[part 1 of 2: package /Vehicle_CAN_Bus_J1939/Clusters]
AUTOSAR XML (schema 4-1-3)
package /Vehicle_CAN_Bus_J1939/Clusters
  can cluster Vehicle_CAN_Bus_J1939
    can physical channel CANChannel
      comm-connectors:
        Thermal_Management_System_ECU_CANConnector
        DMU_VEDS_CANConnector
        VIC_CANConnector
        Vehicle_Control_Unit_CANConnector
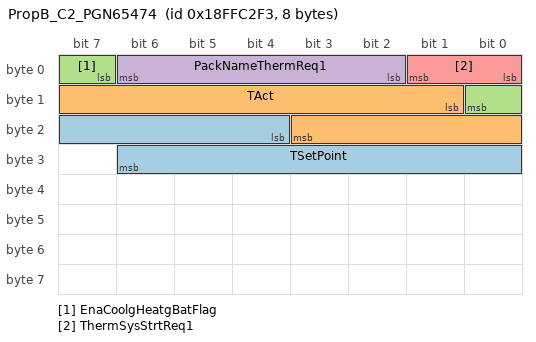
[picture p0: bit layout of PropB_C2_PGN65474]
      frame PropB_C2_PGN65474: id 0x18FFC2F3, from VIC, to Thermal_Management_System_ECU, frame-length=8, can-addressing-mode=EXTENDED  # Coolant/heating request for an external thermal management system with setpoint control
        pdu PropB_C2_PGN65474: length=8, transmission-mode-condition{data-filter=data-filter-type=ALWAYS, i-signal-in-i-pdu=PropB_C2_PGN65474_TSetPoint}, transmission-mode-true-timing=cyclic-timing=time-period=0.1
          signal TSetPoint: start 20, 11 bit, little-endian, data-type-policy=OVERRIDE, init-value=1024, base-type=TSetPoint_Coding, compu {phys=raw*0.25-256; unit °C}, range phys -256..255.75, unit=°C, to Thermal_Management_System_ECU  # Setpoint temperature for an external thermal management system for pack mentioned in PackNameThermReq1 (multiplexed signal)
          signal TAct: start 9, 11 bit, little-endian, data-type-policy=OVERRIDE, init-value=1024, base-type=TAct_Coding, compu {phys=raw*0.25-256; unit °C}, range phys -256..255.75, unit=°C, to Thermal_Management_System_ECU  # Cell temperature of pack mentioned in PackNameThermReq1 with the highest absolute deviation from the setpoint temperature (multiplexed signal)
          signal EnaCoolgHeatgBatFlag: start 7, 2 bit, little-endian, data-type-policy=OVERRIDE, init-value=0, base-type=EnaCoolgHeatgBatFlag_Coding, compu {3=Info not available (default), 2=Reserved, 1=Activate, 0=Deactivate}, range phys 0..3, to Thermal_Management_System_ECU  # Request for coolant/heating flow for an external thermal management system with setpoint control from pack mentioned in PackNameThermReq1 (multiplexed signal)
          signal PackNameThermReq1: start 2, 5 bit, little-endian, data-type-policy=OVERRIDE, init-value=0, base-type=PackNameThermReq1_Coding, compu {31=Info not available, 30=VIC, 12=Pack2_6, 11=Pack2_5, 10=Pack2_4, 9=Pack2_3, 8=Pack2_2, 7=Pack2_1, 6=Pack1_7, 5=Pack1_6, 4=Pack1_5, 3=Pack1_4, 2=Pack1_3, 1=Pack1_2, 0=Pack1_1 or Standalone}, range phys 0..31, to Thermal_Management_System_ECU  # Battery pack the multiplexed signals in this message refer to (multiplexor signal)
          signal ThermSysStrtReq1: start 0, 2 bit, little-endian, data-type-policy=OVERRIDE, init-value=0, base-type=ThermSysStrtReq1_Coding, compu {3=Info not available (default), 2=Reserved, 1=Active, 0=Not active}, range phys 0..3, to Thermal_Management_System_ECU  # Wakeup request for an external thermal management system with setpoint control
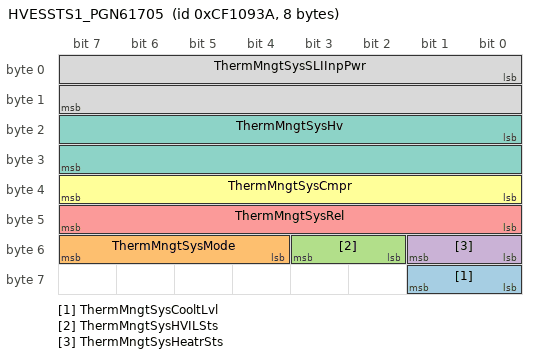
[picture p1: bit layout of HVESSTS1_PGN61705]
      frame HVESSTS1_PGN61705: id 0xCF1093A, from Thermal_Management_System_ECU, to VIC, frame-length=8, can-addressing-mode=EXTENDED  # Collection of data the High Voltage Energy Storage System Thermal Management System sends to the Hybrid Controller.
        pdu HVESSTS1_PGN61705: length=8, transmission-mode-condition{data-filter=data-filter-type=ALWAYS, i-signal-in-i-pdu=HVESSTS1_PGN61705_ThermMngtSysCooltLvl}, transmission-mode-true-timing=cyclic-timing=time-period=0.1
          signal ThermMngtSysCooltLvl: start 56, 2 bit, little-endian, data-type-policy=OVERRIDE, init-value=0, base-type=ThermMngtSysCooltLvl_Coding, compu {3=Not Available, 2=Error, 1=Coolant Level is sufficient, 0=Coolant Level is not sufficient}, range phys 0..3, to VIC  # Indicates the coolant level in the High Voltage Energy Storage System (or Pack 1 in systems with only one pack) Thermal Management System. 00b = Coolant Level is not sufficient 01b = Coolant Level is sufficient 10b = Error 11b = Not Available
          signal ThermMngtSysMode: start 52, 4 bit, little-endian, data-type-policy=OVERRIDE, init-value=0, base-type=ThermMngtSysMode_Coding, compu {15=Not Available, 14=Faulted, 13=Reserved, 12=Reserved, 11=Reserved, 10=Reserved, 9=Reserved, 8=Reserved, 7=Reserved, 6=Reserved, 5=Reserved, 4=Drying, 3=Heating, 2=Cooling, 1=Circulating, 0=Off}, range phys 0..15, to VIC  # Indicates the operating mode of the Thermal Management System.The heat transfer medium may be (e.g. liquid or air). The cooling system may be fans, liquid coolant, or a combination of mediums.
          signal ThermMngtSysHVILSts: start 50, 2 bit, little-endian, data-type-policy=OVERRIDE, init-value=0, base-type=ThermMngtSysHVILSts_Coding, compu {3=Not Available, 2=Error, 1=HVIL Open, 0=HVIL Closed}, range phys 0..3, to VIC  # Status of the High Voltage Interlock Loop from the viewpoint of the High Voltage Energy Storage System Thermal Management System 1. 00b = HVIL Closed 01b = HVIL Open 10b = Error 11b = Not Available
          signal ThermMngtSysHeatrSts: start 48, 2 bit, little-endian, data-type-policy=OVERRIDE, init-value=0, base-type=ThermMngtSysHeatrSts_Coding, compu {3=Not Available, 2=Error, 1=Heater On, 0=Heater Off}, range phys 0..3, to VIC  # The state of the High Voltage Energy Storage System (or Pack 1 in systems with only one pack) heater. 00b = Heater Off 01b = Heater On 10b = Error 11b = Not Available
          signal ThermMngtSysRel: start 40, 8 bit, little-endian, data-type-policy=OVERRIDE, init-value=0, base-type=ThermMngtSysRel_Coding, compu {phys=raw*0.4; unit %}, range phys 0..100, unit=%, to VIC  # When the High Voltage Energy Storage System (or Pack 1 in systems with only one pack) Thermal Management System is equipped with a relative humidity sensor, this is the measured Relative Humidity
          signal ThermMngtSysCmpr: start 32, 8 bit, little-endian, data-type-policy=OVERRIDE, init-value=0, base-type=ThermMngtSysCmpr_Coding, compu {phys=raw*32; unit rpm}, range phys 0..8000, unit=rpm, to VIC  # When the High Voltage Energy Storage System (or Pack 1 in systems with only one pack) Thermal Management System is equipped with an active cooling system (e.g. air conditioner), this is the Compressor Speed.
          signal ThermMngtSysHv: start 16, 16 bit, little-endian, data-type-policy=OVERRIDE, init-value=0, base-type=ThermMngtSysHv_Coding, compu {phys=raw*0.5; unit W}, range phys 0..32127.5, unit=W, to VIC  # This is the high-voltage power consumed by this Thermal Management System (TMS). If there is only one pack, or a single TMS for the entire HVES system, then this represents the total high-voltage power consumed.
          signal ThermMngtSysSLIInpPwr: start 0, 16 bit, little-endian, data-type-policy=OVERRIDE, init-value=0, base-type=ThermMngtSysSLIInpPwr_Coding, compu {phys=raw*0.5; unit W}, range phys 0..32127.5, unit=W, to VIC  # This is the low-voltage power consumed by this Thermal Management System (TMS). If there is only one pack, or a single TMS for the entire HVES system, then this represents the total low-voltage power consumed.
      frame TP_DT_44_PGN60160: id 0x1CEBFFF3, from VIC, frame-length=8, can-addressing-mode=EXTENDED  # - J1939/21 Transport Protocol packets, functional content is defined in the message using the protocol
        pdu TP_DT_44_PGN60160: length=8
          signal Packetized_Data7_TP_DT: start 48, 8 bit, little-endian, data-type-policy=OVERRIDE, init-value=0, base-type=Packetized_Data7_TP_DT_Coding, compu {identical}, range phys 0..255
          signal Packetized_Data6_TP_DT: start 40, 8 bit, little-endian, data-type-policy=OVERRIDE, init-value=0, base-type=Packetized_Data6_TP_DT_Coding, compu {identical}, range phys 0..255
          signal Packetized_Data5_TP_DT: start 32, 8 bit, little-endian, data-type-policy=OVERRIDE, init-value=0, base-type=Packetized_Data5_TP_DT_Coding, compu {identical}, range phys 0..255
          signal Packetized_Data4_TP_DT: start 24, 8 bit, little-endian, data-type-policy=OVERRIDE, init-value=0, base-type=Packetized_Data4_TP_DT_Coding, compu {identical}, range phys 0..255
          signal Packetized_Data3_TP_DT: start 16, 8 bit, little-endian, data-type-policy=OVERRIDE, init-value=0, base-type=Packetized_Data3_TP_DT_Coding, compu {identical}, range phys 0..255
          signal Packetized_Data2_TP_DT: start 8, 8 bit, little-endian, data-type-policy=OVERRIDE, init-value=0, base-type=Packetized_Data2_TP_DT_Coding, compu {identical}, range phys 0..255
          signal Sequence_Number_TP_DT: start 0, 8 bit, little-endian, data-type-policy=OVERRIDE, init-value=0, base-type=Sequence_Number_TP_DT_Coding, compu {identical; unit count}, range phys 0..255, unit=count
      frame TP_CM_44_PGN60416: id 0x1CECFFF3, from VIC, frame-length=8, can-addressing-mode=EXTENDED  # - J1939/21 Transport Protocol packets, functional content is defined in the message using the protocol
        pdu TP_CM_44_PGN60416: length=8
          signal PGN_Packet_Message_BAM: start 40, 24 bit, little-endian, data-type-policy=OVERRIDE, init-value=0, base-type=PGN_Packet_Message_BAM_Coding, compu {identical; unit bit}, range phys 0..16777215, unit=bit
          signal Total_Num_Of_Packet_BAM: start 24, 8 bit, little-endian, data-type-policy=OVERRIDE, init-value=0, base-type=Total_Num_Of_Packet_BAM_Coding, compu {identical; unit count}, range phys 0..255, unit=count
          signal Total_Message_Size_BAM: start 8, 16 bit, little-endian, data-type-policy=OVERRIDE, init-value=9, base-type=Total_Message_Size_BAM_Coding, compu {identical; unit count}, range phys 9..1785, unit=count
          signal Control_Byte_TP_CM: start 0, 8 bit, little-endian, data-type-policy=OVERRIDE, init-value=0, base-type=Control_Byte_TP_CM_Coding, compu {16=RTS, 17=CTS, 19=EoMA, 20=ERTS, 21=ECTS, 22=EDPO, 23=EEoMACK, 24=EAbort, 32=BAM, 255=Abort; unit bit}, range phys 0..255, unit=bit
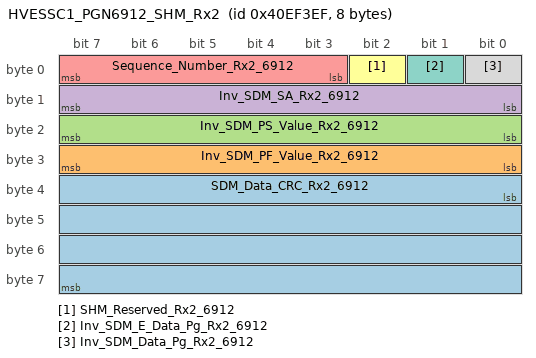
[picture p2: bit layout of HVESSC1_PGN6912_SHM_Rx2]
      frame HVESSC1_PGN6912_SHM_Rx2: id 0x40EF3EF, from DMU_VEDS, to VIC, frame-length=8, can-addressing-mode=EXTENDED  # High Voltage Energy Storage System Control 1
        pdu HVESSC1_PGN6912_SHM_Rx2: length=8, transmission-mode-condition{data-filter=data-filter-type=ALWAYS, i-signal-in-i-pdu=HVESSC1_PGN6912_SHM_Rx2_SDM_Data_CRC_Rx2_6912}, transmission-mode-true-timing=cyclic-timing={time-offset=0.004, time-period=0.02}
          signal SDM_Data_CRC_Rx2_6912: start 32, 32 bit, little-endian, data-type-policy=OVERRIDE, init-value=0, base-type=SDM_Data_CRC_Rx2_6912_Coding, compu {identical}, range phys 0..4294967295, to VIC  # data integrity as the measure for message corruption communication errors. (Ref. J1939-76)
          signal Inv_SDM_PF_Value_Rx2_6912: start 24, 8 bit, little-endian, data-type-policy=OVERRIDE, init-value=0, base-type=Inv_SDM_PF_Value_Rx2_6912_Coding, compu {identical}, range phys 0..255, to VIC
          signal Inv_SDM_PS_Value_Rx2_6912: start 16, 8 bit, little-endian, data-type-policy=OVERRIDE, init-value=0, base-type=Inv_SDM_PS_Value_Rx2_6912_Coding, compu {identical}, range phys 0..255, to VIC
          signal Inv_SDM_SA_Rx2_6912: start 8, 8 bit, little-endian, data-type-policy=OVERRIDE, init-value=0, base-type=Inv_SDM_SA_Rx2_6912_Coding, compu {identical}, range phys 0..255, to VIC
          signal Sequence_Number_Rx2_6912: start 3, 5 bit, little-endian, data-type-policy=OVERRIDE, init-value=0, base-type=Sequence_Number_Rx2_6912_Coding, compu {identical}, range phys 0..31, to VIC  # sequence number increases by 1 for each transmission. (Ref. J1939-76)
          signal SHM_Reserved_Rx2_6912: start 2, 1 bit, little-endian, data-type-policy=OVERRIDE, init-value=0, base-type=SHM_Reserved_Rx2_6912_Coding, compu {identical}, range phys 0..1, to VIC
          signal Inv_SDM_E_Data_Pg_Rx2_6912: start 1, 1 bit, little-endian, data-type-policy=OVERRIDE, init-value=0, base-type=Inv_SDM_E_Data_Pg_Rx2_6912_Coding, compu {identical}, range phys 0..1, to VIC
          signal Inv_SDM_Data_Pg_Rx2_6912: start 0, 1 bit, little-endian, data-type-policy=OVERRIDE, init-value=0, base-type=Inv_SDM_Data_Pg_Rx2_6912_Coding, compu {identical}, range phys 0..1, to VIC
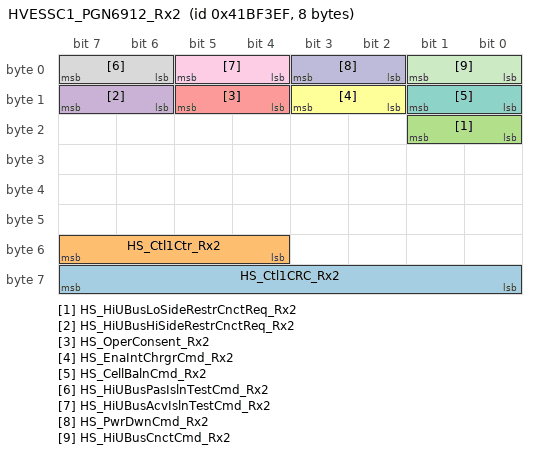
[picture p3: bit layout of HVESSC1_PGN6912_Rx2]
      frame HVESSC1_PGN6912_Rx2: id 0x41BF3EF, from DMU_VEDS, to VIC, frame-length=8, can-addressing-mode=EXTENDED  # High Voltage Energy Storage System Control 1
        pdu HVESSC1_PGN6912_Rx2: length=8, transmission-mode-condition{data-filter=data-filter-type=ALWAYS, i-signal-in-i-pdu=HVESSC1_PGN6912_Rx2_HS_Ctl1CRC_Rx2}, transmission-mode-true-timing=cyclic-timing=time-period=0.02
          signal HS_Ctl1CRC_Rx2: start 56, 8 bit, little-endian, data-type-policy=OVERRIDE, init-value=0, base-type=HS_Ctl1CRC_Rx2_Coding, compu {identical; unit count}, range phys 0..255, unit=count, to VIC  # The CRC is defined as follows: • Length: 8 bits • Polynomial: x^8+x^5+x^3+x^2+x+1 • Initial Value: FFh • Input Data Reflection: Not reflected • Result Data Reflection: Not reflected • XOR value: FFh SAE makes no claim of the functional saf
          signal HS_Ctl1Ctr_Rx2: start 52, 4 bit, little-endian, data-type-policy=OVERRIDE, init-value=0, base-type=HS_Ctl1Ctr_Rx2_Coding, compu {identical; unit bit}, range phys 0..15, unit=bit, to VIC  # The message counter is used to detect situations where the transmitting ECU malfunction repeats the same frame all the time. The receiver of the information may use the counter parameter to detect this situation. The transmitting device will increase the
          signal HS_HiUBusLoSideRestrCnctReq_Rx2: start 16, 2 bit, little-endian, data-type-policy=OVERRIDE, init-value=0, base-type=HS_HiUBusLoSideRestrCnctReq_Rx2_Coding, compu {3=11b = Don't care/take no action, 2=10b = Reserved, 1=01b = Connection Requested, 0=00b = Connection not Requested; unit bit}, range phys 0..3, unit=bit, to VIC  # This parameter is used to request connection of this HVES instance High-Voltage bus low side resistor in order to perform an isolation test. See also SPN 8433 (HVESS Low-Voltage Bus High Side Resistor Connect Request). This parameter provides HVES s
          signal HS_HiUBusHiSideRestrCnctReq_Rx2: start 14, 2 bit, little-endian, data-type-policy=OVERRIDE, init-value=0, base-type=HS_HiUBusHiSideRestrCnctReq_Rx2_Coding, compu {3=11b = Don't care/take no action, 2=10b = Reserved, 1=01b = Connection Requested, 0=00b = Connection not Requested; unit bit}, range phys 0..3, unit=bit, to VIC  # This parameter is used to request connection of this HVES instance High-Voltage bus high side resistor in order to perform an isolation test. See also SPN 8434 (HVESS High-Voltage Bus Low Side Resistor Connect Request). This parameter provides HVES
          signal HS_OperConsent_Rx2: start 12, 2 bit, little-endian, data-type-policy=OVERRIDE, init-value=0, base-type=HS_OperConsent_Rx2_Coding, compu {3=11b = Don't care/Take no action, 2=10b = Error, 1=01b = Consent given; system component consents to HVES instance operation, 0=00b = Consent revoked; system component does not consent to HVES instance operation; unit bit}, range phys 0..3, unit=bit, to VIC  # This parameter provides an indication to the High Voltage Energy Storage System (or Pack 1 in systems with only one pack) that an external device is ready for this HVES instance to proceed with normal operation. In applications which support this parame
          signal HS_EnaIntChrgrCmd_Rx2: start 10, 2 bit, little-endian, data-type-policy=OVERRIDE, init-value=0, base-type=HS_EnaIntChrgrCmd_Rx2_Coding, compu {3=11b = Don't care/Take no action, 2=10b = Reserved, 1=01b = Enable charging, 0=00b = Disable charging; unit bit}, range phys 0..3, unit=bit, to VIC  # When the HVES has an internal charger this parameter will enable it. External chargers may use the External Energy Source Connection Demand (SPN 7890) and related SPs. This parameter provides HVES system level information. If there are multiple pack
          signal HS_CellBalnCmd_Rx2: start 8, 2 bit, little-endian, data-type-policy=OVERRIDE, init-value=0, base-type=HS_CellBalnCmd_Rx2_Coding, compu {3=11b = Don't care/Take no action, 2=10b = Reserved, 1=01b = Cell Balancing requested, 0=00b = Cell Balancing not requested; unit bit}, range phys 0..3, unit=bit, to VIC  # Command for the High Voltage Energy Storage System (or Pack 1 in systems with only one pack) to perform cell balancing. This parameter provides HVES system level information. If there are multiple packs in the system, then both individual pack message
          signal HS_HiUBusPasIslnTestCmd_Rx2: start 6, 2 bit, little-endian, data-type-policy=OVERRIDE, init-value=0, base-type=HS_HiUBusPasIslnTestCmd_Rx2_Coding, compu {3=11b = Don't care/Take no action, 2=10b = Inhibit Passive Isolation Test, 1=01b = Passive Isolation Test request, 0=00b = Passive Isolation Test not requested; unit bit}, range phys 0..3, unit=bit, to VIC  # Command for the High Voltage Energy Storage System (or Pack 1 in systems with only one pack) to perform a passive electrical isolation test on the high voltage bus. A passive isolation test uses additional circuitry (e.g. a high impedance network) to
          signal HS_HiUBusAcvIslnTestCmd_Rx2: start 4, 2 bit, little-endian, data-type-policy=OVERRIDE, init-value=0, base-type=HS_HiUBusAcvIslnTestCmd_Rx2_Coding, compu {3=11b = Don't care/Take no action, 2=10b = Inhibit Active Isolation Test, 1=01b = Active Isolation Test request, 0=00b = Active Isolation Test not requested; unit bit}, range phys 0..3, unit=bit, to VIC  # Command for the High Voltage Energy Storage System (or Pack 1 in systems with only one pack) to perform an active electrical isolation test on the high voltage bus. An active isolation test might use a generated signal (e.g. an injected AC signal) and
          signal HS_PwrDwnCmd_Rx2: start 2, 2 bit, little-endian, data-type-policy=OVERRIDE, init-value=0, base-type=HS_PwrDwnCmd_Rx2_Coding, compu {3=11b = Don't care/Take no action, 2=10b = Execute emergency power-down, 1=01b = Execute normal power-down, 0=00b = Power-down not requested; unit bit}, range phys 0..3, unit=bit, to VIC  # Command to shut down the High Voltage Energy Storage System (or Pack 1 in systems with only one pack). A normal power-down may involve steps that take some period of time (tests, writing of data, etc.). However, an emergency power-down should shut down
          signal HS_HiUBusCnctCmd_Rx2: start 0, 2 bit, little-endian, data-type-policy=OVERRIDE, init-value=0, base-type=HS_HiUBusCnctCmd_Rx2_Coding, compu {3=11b = Don't care/Take no action, 2=10b = Emergency contactor closure request, 1=01b = Close Contactor; Connect HVES to high-voltage bus, 0=00b = Open Contactor; Disconnect HVES from high-voltage bus; unit bit}, range phys 0..3, unit=bit, to VIC  # Command to connect the High Voltage Energy Storage System (or Pack 1 in systems with only one pack) to the high-voltage bus. The emergency contactor closure request may be used in situations where one or more faults in the hybrid powertrain prevent norm
      frame RQST_ES_PGN59904_Rx1: id 0xEAF321, from Vehicle_Control_Unit, to VIC, frame-length=3, can-addressing-mode=EXTENDED  # RQST PGN
        pdu RQST_ES_PGN59904_Rx1: length=3
          signal RQST_Rx1: start 0, 24 bit, little-endian, data-type-policy=OVERRIDE, init-value=0, base-type=RQST_Rx1_Coding, compu {identical}, to VIC  # Upon Requset. To be requested every 5 sec , A request should be sent on 59904 PGN and customer has to support the request handling
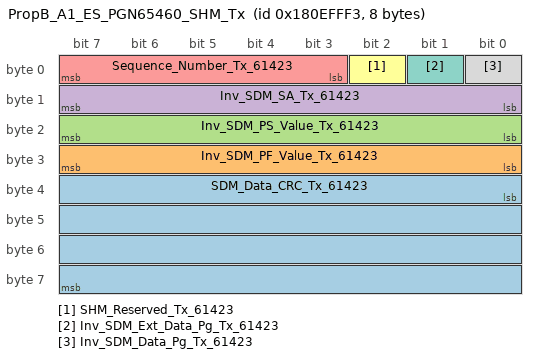
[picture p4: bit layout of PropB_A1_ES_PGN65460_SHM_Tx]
      frame PropB_A1_ES_PGN65460_SHM_Tx: id 0x180EFFF3, from VIC, to DMU_VEDS, frame-length=8, can-addressing-mode=EXTENDED  # Custom PGN
        pdu PropB_A1_ES_PGN65460_SHM_Tx: length=8, transmission-mode-condition{data-filter=data-filter-type=ALWAYS, i-signal-in-i-pdu=PropB_A1_ES_PGN65460_SHM_Tx_SDM_Data_CRC_Tx_61423}, transmission-mode-true-timing=cyclic-timing=time-period=0.02
          signal SDM_Data_CRC_Tx_61423: start 32, 32 bit, little-endian, data-type-policy=OVERRIDE, init-value=0, base-type=SDM_Data_CRC_Tx_61423_Coding, compu {identical}, range phys 0..4294967295, to DMU_VEDS  # data integrity as the measure for message corruption communication errors. (Ref. J1939-76)
          signal Inv_SDM_PF_Value_Tx_61423: start 24, 8 bit, little-endian, data-type-policy=OVERRIDE, init-value=0, base-type=Inv_SDM_PF_Value_Tx_61423_Coding, compu {identical}, range phys 0..255, to DMU_VEDS
          signal Inv_SDM_PS_Value_Tx_61423: start 16, 8 bit, little-endian, data-type-policy=OVERRIDE, init-value=0, base-type=Inv_SDM_PS_Value_Tx_61423_Coding, compu {identical}, range phys 0..255, to DMU_VEDS
          signal Inv_SDM_SA_Tx_61423: start 8, 8 bit, little-endian, data-type-policy=OVERRIDE, init-value=0, base-type=Inv_SDM_SA_Tx_61423_Coding, compu {identical}, range phys 0..255, to DMU_VEDS
          signal Sequence_Number_Tx_61423: start 3, 5 bit, little-endian, data-type-policy=OVERRIDE, init-value=0, base-type=Sequence_Number_Tx_61423_Coding, compu {identical}, range phys 0..31, to DMU_VEDS  # sequence number increases by 1 for each transmission. (Ref. J1939-76)
          signal SHM_Reserved_Tx_61423: start 2, 1 bit, little-endian, data-type-policy=OVERRIDE, init-value=0, base-type=SHM_Reserved_Tx_61423_Coding, compu {identical}, range phys 0..1, to DMU_VEDS
          signal Inv_SDM_Ext_Data_Pg_Tx_61423: start 1, 1 bit, little-endian, data-type-policy=OVERRIDE, init-value=0, base-type=Inv_SDM_Ext_Data_Pg_Tx_61423_Coding, compu {identical}, range phys 0..1, to DMU_VEDS
          signal Inv_SDM_Data_Pg_Tx_61423: start 0, 1 bit, little-endian, data-type-policy=OVERRIDE, init-value=0, base-type=Inv_SDM_Data_Pg_Tx_61423_Coding, compu {identical}, range phys 0..1, to DMU_VEDS
      frame HVESSD3_PGN61586: id 0xCF092F3, from VIC, to Vehicle_Control_Unit, frame-length=8, can-addressing-mode=EXTENDED  # Data set 3 (thermal data) for High Voltage Energy Storage System (or Pack 1 in systems with only one pack).
        pdu HVESSD3_PGN61586: length=8, transmission-mode-condition{data-filter=data-filter-type=ALWAYS, i-signal-in-i-pdu=HVESSD3_PGN61586_HS_CellTempDiffStatus}, transmission-mode-true-timing=cyclic-timing=time-period=0.02
          signal HS_CellTempDiffStatus: start 48, 2 bit, little-endian, data-type-policy=OVERRIDE, init-value=0, base-type=HS_CellTempDiffStatus_Coding, compu {identical; unit bit}, range phys 0..3, unit=bit, to Vehicle_Control_Unit  # Indicates whether or not the differential between the highest and lowest cell temperatures are within acceptable limits per the High Voltage Energy Storage System (or Pack 1 in systems with only one pack).
          signal HS_AvgCellTemp: start 32, 16 bit, little-endian, data-type-policy=OVERRIDE, init-value=8736, base-type=HS_AvgCellTemp_Coding, compu {phys=raw/32-273; unit °C}, range phys -273..1734.96875, unit=°C, to Vehicle_Control_Unit  # The average temperature level of all cells in the High Voltage Energy Storage System (or Pack 1 in systems with only one pack).
          signal HS_LowCellTemp: start 16, 16 bit, little-endian, data-type-policy=OVERRIDE, init-value=8736, base-type=HS_LowCellTemp_Coding, compu {phys=raw/32-273; unit °C}, range phys -273..1734.96875, unit=°C, to Vehicle_Control_Unit  # The lowest temperature level reported by any cell in the High Voltage Energy Storage System (or Pack 1 in systems with only one pack).
          signal HS_HiCellTemp: start 0, 16 bit, little-endian, data-type-policy=OVERRIDE, init-value=8736, base-type=HS_HiCellTemp_Coding, compu {phys=raw/32-273; unit °C}, range phys -273..1734.96875, unit=°C, to Vehicle_Control_Unit  # The highest temperature level reported by any cell in the High Voltage Energy Storage System (or Pack 1 in systems with only one pack).
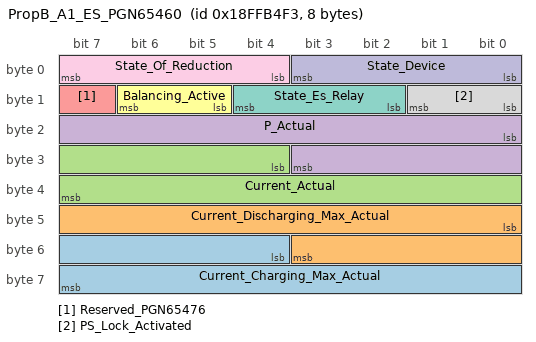
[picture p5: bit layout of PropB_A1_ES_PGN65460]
      frame PropB_A1_ES_PGN65460: id 0x18FFB4F3, from VIC, to DMU_VEDS, frame-length=8, can-addressing-mode=EXTENDED  # Custom PGN
        pdu PropB_A1_ES_PGN65460: length=8, transmission-mode-condition{data-filter=data-filter-type=ALWAYS, i-signal-in-i-pdu=PropB_A1_ES_PGN65460_Current_Charging_Max_Actual}, transmission-mode-true-timing=cyclic-timing=time-period=0.02
          signal Current_Charging_Max_Actual: start 52, 12 bit, little-endian, data-type-policy=OVERRIDE, init-value=2000, base-type=Current_Charging_Max_Actual_Coding, compu {phys=raw-2000; unit A}, range phys -2000..2015, unit=A, to DMU_VEDS  # Maximum Charging current.
          signal Current_Discharging_Max_Actual: start 40, 12 bit, little-endian, data-type-policy=OVERRIDE, init-value=2000, base-type=Current_Discharging_Max_Actual_Coding, compu {phys=raw-2000; unit A}, range phys -2000..2015, unit=A, to DMU_VEDS  # Maximum discharging current.
          signal Current_Actual: start 28, 12 bit, little-endian, data-type-policy=OVERRIDE, init-value=2000, base-type=Current_Actual_Coding, compu {phys=raw-2000; unit A}, range phys -2000..2015, unit=A, to DMU_VEDS  # Actual value of the energy storage current.
          signal P_Actual: start 16, 12 bit, little-endian, data-type-policy=OVERRIDE, init-value=2000, base-type=P_Actual_Coding, compu {phys=raw*250-500000; unit W}, range phys -500000..503750, unit=W, to DMU_VEDS  # Actual value of the energy storage power.
          signal Reserved_PGN65476: start 15, 1 bit, little-endian, data-type-policy=OVERRIDE, init-value=0, base-type=Reserved_PGN65476_Coding, compu {identical; unit bit}, range phys 0..1, unit=bit, to DMU_VEDS  # reserved.
          signal Balancing_Active: start 13, 2 bit, little-endian, data-type-policy=OVERRIDE, init-value=0, base-type=Balancing_Active_Coding, compu {identical; unit bit}, range phys 0..3, unit=bit, to DMU_VEDS  # Indicates whether the balancing function of the energy storage is active.
          signal State_Es_Relay: start 10, 3 bit, little-endian, data-type-policy=OVERRIDE, init-value=0, base-type=State_Es_Relay_Coding, compu {7=111b = Not available, 6=110b = Error, 5=101b = reserved, 4=100b = Main Relays opening, 3=11b = Main Relays closed, 2=10b = All Es-Relays closed, 1=01b = PreCharge-Relais closed, 0=00b = All Es-Relays open; unit bit}, range phys 0..7, unit=bit, to DMU_VEDS  # State of the energy storage relays.
          signal PS_Lock_Activated: start 8, 2 bit, little-endian, data-type-policy=OVERRIDE, init-value=0, base-type=PS_Lock_Activated_Coding, compu {3=11b = Not available, 2=10b = Lock is activated by ESCU, 1=01b = Lock is activated by HTCU, 0=00b = Lock is inactive; unit bit}, range phys 0..3, unit=bit, to DMU_VEDS  # Indicates whether the electrical power supply lock of the ESCU is activated by the HTCU or by the component itself due to an internal reason.
          signal State_Of_Reduction: start 4, 4 bit, little-endian, data-type-policy=OVERRIDE, init-value=0, base-type=State_Of_Reduction_Coding, compu {identical}, range phys 0..15, to DMU_VEDS  # Indicates the cause why the component limitation is active.
          signal State_Device: start 0, 4 bit, little-endian, data-type-policy=OVERRIDE, init-value=0, base-type=State_Device_Coding, compu {identical}, range phys 0..15, to DMU_VEDS  # Indicates the current device state.
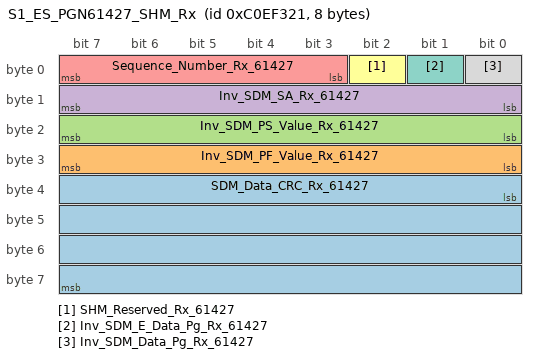
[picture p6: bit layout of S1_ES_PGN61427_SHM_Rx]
      frame S1_ES_PGN61427_SHM_Rx: id 0xC0EF321, from Vehicle_Control_Unit, to VIC, frame-length=8, can-addressing-mode=EXTENDED  # HvReq Connect
        pdu S1_ES_PGN61427_SHM_Rx: length=8, transmission-mode-condition{data-filter=data-filter-type=ALWAYS, i-signal-in-i-pdu=S1_ES_PGN61427_SHM_Rx_SDM_Data_CRC_Rx_61427}, transmission-mode-true-timing=cyclic-timing=time-period=0.02
          signal SDM_Data_CRC_Rx_61427: start 32, 32 bit, little-endian, data-type-policy=OVERRIDE, init-value=0, base-type=SDM_Data_CRC_Rx_61427_Coding, compu {identical}, range phys 0..4294967295, to VIC  # data integrity as the measure for message corruption communication errors. (Ref. J1939-76)
          signal Inv_SDM_PF_Value_Rx_61427: start 24, 8 bit, little-endian, data-type-policy=OVERRIDE, init-value=0, base-type=Inv_SDM_PF_Value_Rx_61427_Coding, compu {identical}, range phys 0..255, to VIC
          signal Inv_SDM_PS_Value_Rx_61427: start 16, 8 bit, little-endian, data-type-policy=OVERRIDE, init-value=0, base-type=Inv_SDM_PS_Value_Rx_61427_Coding, compu {identical}, range phys 0..255, to VIC
          signal Inv_SDM_SA_Rx_61427: start 8, 8 bit, little-endian, data-type-policy=OVERRIDE, init-value=0, base-type=Inv_SDM_SA_Rx_61427_Coding, compu {identical}, range phys 0..255, to VIC
          signal Sequence_Number_Rx_61427: start 3, 5 bit, little-endian, data-type-policy=OVERRIDE, init-value=0, base-type=Sequence_Number_Rx_61427_Coding, compu {identical}, range phys 0..31, to VIC  # sequence number increases by 1 for each transmission. (Ref. J1939-76)
          signal SHM_Reserved_Rx_61427: start 2, 1 bit, little-endian, data-type-policy=OVERRIDE, init-value=0, base-type=SHM_Reserved_Rx_61427_Coding, compu {identical}, range phys 0..1, to VIC
          signal Inv_SDM_E_Data_Pg_Rx_61427: start 1, 1 bit, little-endian, data-type-policy=OVERRIDE, init-value=0, base-type=Inv_SDM_E_Data_Pg_Rx_61427_Coding, compu {identical}, range phys 0..1, to VIC
          signal Inv_SDM_Data_Pg_Rx_61427: start 0, 1 bit, little-endian, data-type-policy=OVERRIDE, init-value=0, base-type=Inv_SDM_Data_Pg_Rx_61427_Coding, compu {identical}, range phys 0..1, to VIC
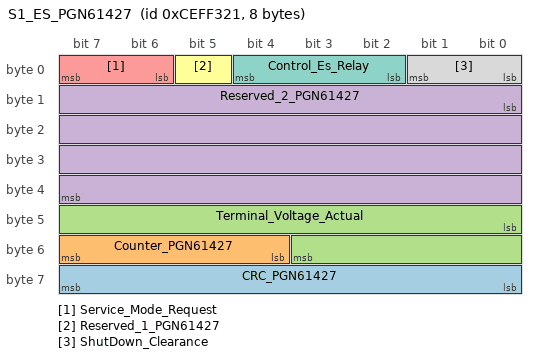
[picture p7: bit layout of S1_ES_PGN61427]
      frame S1_ES_PGN61427: id 0xCEFF321, from Vehicle_Control_Unit, to VIC, frame-length=8, can-addressing-mode=EXTENDED  # Set Point Message_1 – Energy Storage
        pdu S1_ES_PGN61427: length=8, transmission-mode-condition{data-filter=data-filter-type=ALWAYS, i-signal-in-i-pdu=S1_ES_PGN61427_CRC_PGN61427}, transmission-mode-true-timing=cyclic-timing=time-period=0.02
          signal CRC_PGN61427: start 56, 8 bit, little-endian, data-type-policy=OVERRIDE, init-value=0, base-type=CRC_PGN61427_Coding, compu {identical; unit unit}, range phys 0..255, unit=unit, to VIC  # The end-to-end crc is calculated over the first seven bytes of the CAN frame. The end-to-end crc is calculated with the WCDMA-8 (x^8 +x^7 +x^4 +x^3 +x +1) polynomial.
          signal Counter_PGN61427: start 52, 4 bit, little-endian, data-type-policy=OVERRIDE, init-value=0, base-type=Counter_PGN61427_Coding, compu {identical; unit unit}, range phys 0..15, unit=unit, to VIC  # The message counter is incremented by one for each new message. If the message counter exceeds the message counter maximum value, it start again by 0. If the message counter does not match the expected value, the received data is invalid.
          signal Terminal_Voltage_Actual: start 40, 12 bit, little-endian, data-type-policy=OVERRIDE, init-value=0, base-type=Terminal_Voltage_Actual_Coding, compu {phys=raw*0.5; unit V}, range phys 0..2007.5, unit=V, to VIC  # Actual value of the terminal voltage, measured before the main contactor.
          signal Reserved_2_PGN61427: start 8, 32 bit, little-endian, data-type-policy=OVERRIDE, init-value=0, base-type=Reserved_2_PGN61427_Coding, compu {identical; unit unit}, range phys 0..4294967295, unit=unit, to VIC
          signal Service_Mode_Request: start 6, 2 bit, little-endian, data-type-policy=OVERRIDE, init-value=0, base-type=Service_Mode_Request_Coding, compu {identical; unit bit}, range phys 0..3, unit=bit, to VIC  # By means of the serviceModeRequest signal the component can be put into to the service mode. 0x0 = Service mode not requested 0x1 = Service mode requested 0x2 = Reserved 0x3 = Not available
          signal Reserved_1_PGN61427: start 5, 1 bit, little-endian, data-type-policy=OVERRIDE, init-value=0, base-type=Reserved_1_PGN61427_Coding, compu {identical; unit unit}, range phys 0..1, unit=unit, to VIC
          signal Control_Es_Relay: start 2, 3 bit, little-endian, data-type-policy=OVERRIDE, init-value=0, base-type=Control_Es_Relay_Coding, compu {7=111b = info not available, 6=110b = disconnect DC char, 5=101b = connect for DC char, 4=100b = prepare for DC char, 3=11b = connect for driving, 2=10b = connect for AC char, 1=01b = emergency disconnect, 0=00b = disconnect; unit bit}, range phys 0..7, unit=bit, to VIC  # Control command for the activation/deactivation of the energy storage relays.
          signal ShutDown_Clearance: start 0, 2 bit, little-endian, data-type-policy=OVERRIDE, init-value=0, base-type=ShutDown_Clearance_Coding, compu {identical; unit bit}, range phys 0..3, unit=bit, to VIC  # Signal for prevention of an undesirable shut down of the ESCU during normal system operation. 0x0 = Component shut down not granted 0x1 = Component shut down granted 0x2 = Reserved 0x3 = Not available
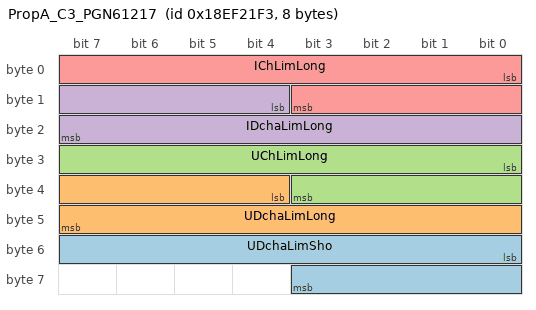
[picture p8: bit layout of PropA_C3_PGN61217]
      frame PropA_C3_PGN61217: id 0x18EF21F3, from VIC, to Vehicle_Control_Unit, frame-length=8, can-addressing-mode=EXTENDED  # Custom PGN
        pdu PropA_C3_PGN61217: length=8, transmission-mode-condition{data-filter=data-filter-type=ALWAYS, i-signal-in-i-pdu=PropA_C3_PGN61217_UDchaLimSho}, transmission-mode-true-timing=cyclic-timing=time-period=0.02
          signal UDchaLimSho: start 48, 12 bit, little-endian, data-type-policy=OVERRIDE, init-value=0, base-type=UDchaLimSho_Coding, compu {phys=raw*0.25; unit V}, range phys 0..1023.75, unit=V  # This signal contains the short term voltage limit for discharging the battery system.
          signal UDchaLimLong: start 36, 12 bit, little-endian, data-type-policy=OVERRIDE, init-value=0, base-type=UDchaLimLong_Coding, compu {phys=raw*0.25; unit V}, range phys 0..1023.75, unit=V  # This signal contains the long term voltage limit for discharging the battery system.
          signal UChLimLong: start 24, 12 bit, little-endian, data-type-policy=OVERRIDE, init-value=0, base-type=UChLimLong_Coding, compu {phys=raw*0.25; unit V}, range phys 0..1023.75, unit=V  # This signal contains the long term voltage limit for charging the battery system.
          signal IDchaLimLong: start 12, 12 bit, little-endian, data-type-policy=OVERRIDE, init-value=0, base-type=IDchaLimLong_Coding, compu {phys=raw*0.5; unit A}, range phys 0..1023.75, unit=A  # This signal contains the long term current limit for discharging the battery system.
          signal IChLimLong: start 0, 12 bit, little-endian, data-type-policy=OVERRIDE, init-value=0, base-type=IChLimLong_Coding, compu {phys=raw*0.5; unit A}, range phys 0..1023.75, unit=A, to Vehicle_Control_Unit  # This signal contains the long term current limit for charging the battery system.
      frame RQST_ES_PGN59904_Tx: id 0xEA21F3, from VIC, to Vehicle_Control_Unit, frame-length=3, can-addressing-mode=EXTENDED
        pdu RQST_ES_PGN59904_Tx: length=3, transmission-mode-condition{data-filter=data-filter-type=ALWAYS, i-signal-in-i-pdu=RQST_ES_PGN59904_Tx_RQST_Tx}, transmission-mode-true-timing=cyclic-timing=time-period=1
          signal RQST_Tx: start 0, 24 bit, little-endian, data-type-policy=OVERRIDE, init-value=0, base-type=RQST_Tx_Coding, compu {identical; unit unit}, range phys 0..16777215, unit=unit, to Vehicle_Control_Unit  # To be transmit every 5 sec , A request should be sent on 59904 PGN and customer has to support the request handling
      frame DM01_44: id 0x18FECAF3, from VIC, frame-length=42, can-addressing-mode=EXTENDED  # The message is sent cyclic and on change
        pdu DM01_44: length=42
          signal Flash_Mil: start 14, 2 bit, little-endian, data-type-policy=OVERRIDE, init-value=0, base-type=Flash_Mil_Coding, compu {3=Unavailable/Do Not Flash, 0=Slow Flash, 1=Fast Flash, 2=Class C DTC}, range phys 0..3  # Flash Malfunction Indication Lamp
          signal Flash_Rsl: start 12, 2 bit, little-endian, data-type-policy=OVERRIDE, init-value=0, base-type=Flash_Rsl_Coding, compu {3=Unavailable/Do Not Flash, 2=Reserved, 0=Slow Flash, 1=Fast Flash}, range phys 0..3  # Flash Red Stop Lamp
          signal Flash_Awl: start 10, 2 bit, little-endian, data-type-policy=OVERRIDE, init-value=0, base-type=Flash_Awl_Coding, compu {3=Unavailable/Do Not Flash, 2=Reserved, 0=Slow Flash, 1=Fast Flash}, range phys 0..3  # Flash Amber Warning Lamp
          signal Flash_ProtLamp: start 8, 2 bit, little-endian, data-type-policy=OVERRIDE, init-value=0, base-type=Flash_ProtLamp_Coding, compu {3=Unavailable/Do Not Flash, 2=Reserved, 0=Slow Flash, 1=Fast Flash}, range phys 0..3  # Flash Protect Lamp
          signal ProtLamp: start 0, 2 bit, little-endian, data-type-policy=OVERRIDE, init-value=0, base-type=ProtLamp_Coding, compu {0=Off, 1=On}, range phys 0..1
          signal Awl: start 2, 2 bit, little-endian, data-type-policy=OVERRIDE, init-value=0, base-type=Awl_Coding, compu {0=Off, 1=On}, range phys 0..1
          signal Rsl: start 4, 2 bit, little-endian, data-type-policy=OVERRIDE, init-value=0, base-type=Rsl_Coding, compu {0=Off, 1=On}, range phys 0..1
          signal Mil: start 6, 2 bit, little-endian, data-type-policy=OVERRIDE, init-value=0, base-type=Mil_Coding, compu {0=Off, 1=On, 2=Short MIL}, range phys 0..2
          signal Spn01: start 16, 16 bit, little-endian, data-type-policy=OVERRIDE, init-value=0, base-type=Spn01_Coding, compu {identical; unit binary}, range phys 0..65535, unit=binary
          signal SpnHigh01: start 37, 3 bit, little-endian, data-type-policy=OVERRIDE, init-value=0, base-type=SpnHigh01_Coding, compu {identical; unit binary}, range phys 0..7, unit=binary
          signal Fmi01: start 32, 5 bit, little-endian, data-type-policy=OVERRIDE, init-value=0, base-type=Fmi01_Coding, compu {0=Data Above Normal, Most severe, 1=Data Below Normal, Most severe, 2=Data erratic, interm, incorrect, 3=Voltage above normal, SC High, 4=Voltage below normal, SC Low, 5=Current below normal, OC, 6=Current above normal, SC, 7=Mech. system not responding, 8=Abnormal Freq, Width, Period, 9=Abnormal Update Rate, 10=Abnormal Rate Of Change, 11=Root Cause Not Known, 12=Bad Intell. Device, Component, 13=Out Of Calibration, 14=Special Instructions, 15=Data Above Normal, Least severe, 16=Data Above Normal, Moder. severe, 17=Data Below Normal, Least Severe, 18=Data Below Normal, Moder. severe, 19=Received Network Data In Error, 20=Data Drifted High, 21=Data Drifted Low, 31=Condition Exists; unit binary}, range phys 0..31, unit=binary
          signal Oc01: start 40, 7 bit, little-endian, data-type-policy=OVERRIDE, init-value=0, base-type=Oc01_Coding, compu {127=Not Available; unit binary}, range phys 0..127, unit=binary
          signal SpnCm01: start 47, 1 bit, little-endian, data-type-policy=OVERRIDE, init-value=0, base-type=SpnCm01_Coding, compu {0=SPN v.4, 1=SPN v.1,2,3}, range phys 0..1
          signal Spn02: start 48, 16 bit, little-endian, data-type-policy=OVERRIDE, init-value=0, base-type=Spn02_Coding, compu {identical; unit binary}, range phys 0..65535, unit=binary
          signal SpnHigh02: start 69, 3 bit, little-endian, data-type-policy=OVERRIDE, init-value=0, base-type=SpnHigh02_Coding, compu {identical; unit binary}, range phys 0..7, unit=binary
          signal Fmi02: start 64, 5 bit, little-endian, data-type-policy=OVERRIDE, init-value=0, base-type=Fmi02_Coding, compu {0=Data Above Normal, Most severe, 1=Data Below Normal, Most severe, 2=Data erratic, interm, incorrect, 3=Voltage above normal, SC High, 4=Voltage below normal, SC Low, 5=Current below normal, OC, 6=Current above normal, SC, 7=Mech. system not responding, 8=Abnormal Freq, Width, Period, 9=Abnormal Update Rate, 10=Abnormal Rate Of Change, 11=Root Cause Not Known, 12=Bad Intell. Device, Component, 13=Out Of Calibration, 14=Special Instructions, 15=Data Above Normal, Least severe, 16=Data Above Normal, Moder. severe, 17=Data Below Normal, Least Severe, 18=Data Below Normal, Moder. severe, 19=Received Network Data In Error, 20=Data Drifted High, 21=Data Drifted Low, 31=Condition Exists; unit binary}, range phys 0..31, unit=binary
          signal Oc02: start 72, 7 bit, little-endian, data-type-policy=OVERRIDE, init-value=0, base-type=Oc02_Coding, compu {127=Not Available; unit binary}, range phys 0..127, unit=binary
          signal SpnCm02: start 79, 1 bit, little-endian, data-type-policy=OVERRIDE, init-value=0, base-type=SpnCm02_Coding, compu {0=SPN v.4, 1=SPN v.1,2,3}, range phys 0..1
          signal Spn03: start 80, 16 bit, little-endian, data-type-policy=OVERRIDE, init-value=0, base-type=Spn03_Coding, compu {identical; unit binary}, range phys 0..65535, unit=binary
          signal SpnHigh03: start 101, 3 bit, little-endian, data-type-policy=OVERRIDE, init-value=0, base-type=SpnHigh03_Coding, compu {identical; unit binary}, range phys 0..7, unit=binary
          signal Fmi03: start 96, 5 bit, little-endian, data-type-policy=OVERRIDE, init-value=0, base-type=Fmi03_Coding, compu {0=Data Above Normal, Most severe, 1=Data Below Normal, Most severe, 2=Data erratic, interm, incorrect, 3=Voltage above normal, SC High, 4=Voltage below normal, SC Low, 5=Current below normal, OC, 6=Current above normal, SC, 7=Mech. system not responding, 8=Abnormal Freq, Width, Period, 9=Abnormal Update Rate, 10=Abnormal Rate Of Change, 11=Root Cause Not Known, 12=Bad Intell. Device, Component, 13=Out Of Calibration, 14=Special Instructions, 15=Data Above Normal, Least severe, 16=Data Above Normal, Moder. severe, 17=Data Below Normal, Least Severe, 18=Data Below Normal, Moder. severe, 19=Received Network Data In Error, 20=Data Drifted High, 21=Data Drifted Low, 31=Condition Exists; unit binary}, range phys 0..31, unit=binary
          signal Oc03: start 104, 7 bit, little-endian, data-type-policy=OVERRIDE, init-value=0, base-type=Oc03_Coding, compu {127=Not Available; unit binary}, range phys 0..127, unit=binary
          signal SpnCm03: start 111, 1 bit, little-endian, data-type-policy=OVERRIDE, init-value=0, base-type=SpnCm03_Coding, compu {0=SPN v.4, 1=SPN v.1,2,3}, range phys 0..1
          signal Spn04: start 112, 16 bit, little-endian, data-type-policy=OVERRIDE, init-value=0, base-type=Spn04_Coding, compu {identical; unit binary}, range phys 0..65535, unit=binary
          signal SpnHigh04: start 133, 3 bit, little-endian, data-type-policy=OVERRIDE, init-value=0, base-type=SpnHigh04_Coding, compu {identical; unit binary}, range phys 0..7, unit=binary
          signal Fmi04: start 128, 5 bit, little-endian, data-type-policy=OVERRIDE, init-value=0, base-type=Fmi04_Coding, compu {0=Data Above Normal, Most severe, 1=Data Below Normal, Most severe, 2=Data erratic, interm, incorrect, 3=Voltage above normal, SC High, 4=Voltage below normal, SC Low, 5=Current below normal, OC, 6=Current above normal, SC, 7=Mech. system not responding, 8=Abnormal Freq, Width, Period, 9=Abnormal Update Rate, 10=Abnormal Rate Of Change, 11=Root Cause Not Known, 12=Bad Intell. Device, Component, 13=Out Of Calibration, 14=Special Instructions, 15=Data Above Normal, Least severe, 16=Data Above Normal, Moder. severe, 17=Data Below Normal, Least Severe, 18=Data Below Normal, Moder. severe, 19=Received Network Data In Error, 20=Data Drifted High, 21=Data Drifted Low, 31=Condition Exists; unit binary}, range phys 0..31, unit=binary
          signal Oc04: start 136, 7 bit, little-endian, data-type-policy=OVERRIDE, init-value=0, base-type=Oc04_Coding, compu {127=Not Available; unit binary}, range phys 0..127, unit=binary
          signal SpnCm04: start 143, 1 bit, little-endian, data-type-policy=OVERRIDE, init-value=0, base-type=SpnCm04_Coding, compu {0=SPN v.4, 1=SPN v.1,2,3}, range phys 0..1
          signal Spn05: start 144, 16 bit, little-endian, data-type-policy=OVERRIDE, init-value=0, base-type=Spn05_Coding, compu {identical; unit binary}, range phys 0..65535, unit=binary
          signal SpnHigh05: start 165, 3 bit, little-endian, data-type-policy=OVERRIDE, init-value=0, base-type=SpnHigh05_Coding, compu {identical; unit binary}, range phys 0..7, unit=binary
          signal Fmi05: start 160, 5 bit, little-endian, data-type-policy=OVERRIDE, init-value=0, base-type=Fmi05_Coding, compu {0=Data Above Normal, Most severe, 1=Data Below Normal, Most severe, 2=Data erratic, interm, incorrect, 3=Voltage above normal, SC High, 4=Voltage below normal, SC Low, 5=Current below normal, OC, 6=Current above normal, SC, 7=Mech. system not responding, 8=Abnormal Freq, Width, Period, 9=Abnormal Update Rate, 10=Abnormal Rate Of Change, 11=Root Cause Not Known, 12=Bad Intell. Device, Component, 13=Out Of Calibration, 14=Special Instructions, 15=Data Above Normal, Least severe, 16=Data Above Normal, Moder. severe, 17=Data Below Normal, Least Severe, 18=Data Below Normal, Moder. severe, 19=Received Network Data In Error, 20=Data Drifted High, 21=Data Drifted Low, 31=Condition Exists; unit binary}, range phys 0..31, unit=binary
          signal Oc05: start 168, 7 bit, little-endian, data-type-policy=OVERRIDE, init-value=0, base-type=Oc05_Coding, compu {127=Not Available; unit binary}, range phys 0..127, unit=binary
          signal SpnCm05: start 175, 1 bit, little-endian, data-type-policy=OVERRIDE, init-value=0, base-type=SpnCm05_Coding, compu {0=SPN v.4, 1=SPN v.1,2,3}, range phys 0..1
          signal Spn06: start 176, 16 bit, little-endian, data-type-policy=OVERRIDE, init-value=0, base-type=Spn06_Coding, compu {identical; unit binary}, range phys 0..65535, unit=binary
          signal SpnHigh06: start 197, 3 bit, little-endian, data-type-policy=OVERRIDE, init-value=0, base-type=SpnHigh06_Coding, compu {identical; unit binary}, range phys 0..7, unit=binary
          signal Fmi06: start 192, 5 bit, little-endian, data-type-policy=OVERRIDE, init-value=0, base-type=Fmi06_Coding, compu {0=Data Above Normal, Most severe, 1=Data Below Normal, Most severe, 2=Data erratic, interm, incorrect, 3=Voltage above normal, SC High, 4=Voltage below normal, SC Low, 5=Current below normal, OC, 6=Current above normal, SC, 7=Mech. system not responding, 8=Abnormal Freq, Width, Period, 9=Abnormal Update Rate, 10=Abnormal Rate Of Change, 11=Root Cause Not Known, 12=Bad Intell. Device, Component, 13=Out Of Calibration, 14=Special Instructions, 15=Data Above Normal, Least severe, 16=Data Above Normal, Moder. severe, 17=Data Below Normal, Least Severe, 18=Data Below Normal, Moder. severe, 19=Received Network Data In Error, 20=Data Drifted High, 21=Data Drifted Low, 31=Condition Exists; unit binary}, range phys 0..31, unit=binary
          signal Oc06: start 200, 7 bit, little-endian, data-type-policy=OVERRIDE, init-value=0, base-type=Oc06_Coding, compu {127=Not Available; unit binary}, range phys 0..127, unit=binary
          signal SpnCm06: start 207, 1 bit, little-endian, data-type-policy=OVERRIDE, init-value=0, base-type=SpnCm06_Coding, compu {0=SPN v.4, 1=SPN v.1,2,3}, range phys 0..1
          signal Spn07: start 208, 16 bit, little-endian, data-type-policy=OVERRIDE, init-value=0, base-type=Spn07_Coding, compu {identical; unit binary}, range phys 0..65535, unit=binary
          signal SpnHigh07: start 229, 3 bit, little-endian, data-type-policy=OVERRIDE, init-value=0, base-type=SpnHigh07_Coding, compu {identical; unit binary}, range phys 0..7, unit=binary
          signal Fmi07: start 224, 5 bit, little-endian, data-type-policy=OVERRIDE, init-value=0, base-type=Fmi07_Coding, compu {0=Data Above Normal, Most severe, 1=Data Below Normal, Most severe, 2=Data erratic, interm, incorrect, 3=Voltage above normal, SC High, 4=Voltage below normal, SC Low, 5=Current below normal, OC, 6=Current above normal, SC, 7=Mech. system not responding, 8=Abnormal Freq, Width, Period, 9=Abnormal Update Rate, 10=Abnormal Rate Of Change, 11=Root Cause Not Known, 12=Bad Intell. Device, Component, 13=Out Of Calibration, 14=Special Instructions, 15=Data Above Normal, Least severe, 16=Data Above Normal, Moder. severe, 17=Data Below Normal, Least Severe, 18=Data Below Normal, Moder. severe, 19=Received Network Data In Error, 20=Data Drifted High, 21=Data Drifted Low, 31=Condition Exists; unit binary}, range phys 0..31, unit=binary
          signal Oc07: start 232, 7 bit, little-endian, data-type-policy=OVERRIDE, init-value=0, base-type=Oc07_Coding, compu {127=Not Available; unit binary}, range phys 0..127, unit=binary
          signal SpnCm07: start 239, 1 bit, little-endian, data-type-policy=OVERRIDE, init-value=0, base-type=SpnCm07_Coding, compu {0=SPN v.4, 1=SPN v.1,2,3}, range phys 0..1
          signal Spn08: start 240, 16 bit, little-endian, data-type-policy=OVERRIDE, init-value=0, base-type=Spn08_Coding, compu {identical; unit binary}, range phys 0..65535, unit=binary
          signal SpnHigh08: start 261, 3 bit, little-endian, data-type-policy=OVERRIDE, init-value=0, base-type=SpnHigh08_Coding, compu {identical; unit binary}, range phys 0..7, unit=binary
          signal Fmi08: start 256, 5 bit, little-endian, data-type-policy=OVERRIDE, init-value=0, base-type=Fmi08_Coding, compu {0=Data Above Normal, Most severe, 1=Data Below Normal, Most severe, 2=Data erratic, interm, incorrect, 3=Voltage above normal, SC High, 4=Voltage below normal, SC Low, 5=Current below normal, OC, 6=Current above normal, SC, 7=Mech. system not responding, 8=Abnormal Freq, Width, Period, 9=Abnormal Update Rate, 10=Abnormal Rate Of Change, 11=Root Cause Not Known, 12=Bad Intell. Device, Component, 13=Out Of Calibration, 14=Special Instructions, 15=Data Above Normal, Least severe, 16=Data Above Normal, Moder. severe, 17=Data Below Normal, Least Severe, 18=Data Below Normal, Moder. severe, 19=Received Network Data In Error, 20=Data Drifted High, 21=Data Drifted Low, 31=Condition Exists; unit binary}, range phys 0..31, unit=binary
          signal Oc08: start 264, 7 bit, little-endian, data-type-policy=OVERRIDE, init-value=0, base-type=Oc08_Coding, compu {127=Not Available; unit binary}, range phys 0..127, unit=binary
          signal SpnCm08: start 271, 1 bit, little-endian, data-type-policy=OVERRIDE, init-value=0, base-type=SpnCm08_Coding, compu {0=SPN v.4, 1=SPN v.1,2,3}, range phys 0..1
          signal Spn09: start 272, 16 bit, little-endian, data-type-policy=OVERRIDE, init-value=0, base-type=Spn09_Coding, compu {identical; unit binary}, range phys 0..65535, unit=binary
          signal SpnHigh09: start 293, 3 bit, little-endian, data-type-policy=OVERRIDE, init-value=0, base-type=SpnHigh09_Coding, compu {identical; unit binary}, range phys 0..7, unit=binary
          signal Fmi09: start 288, 5 bit, little-endian, data-type-policy=OVERRIDE, init-value=0, base-type=Fmi09_Coding, compu {0=Data Above Normal, Most severe, 1=Data Below Normal, Most severe, 2=Data erratic, interm, incorrect, 3=Voltage above normal, SC High, 4=Voltage below normal, SC Low, 5=Current below normal, OC, 6=Current above normal, SC, 7=Mech. system not responding, 8=Abnormal Freq, Width, Period, 9=Abnormal Update Rate, 10=Abnormal Rate Of Change, 11=Root Cause Not Known, 12=Bad Intell. Device, Component, 13=Out Of Calibration, 14=Special Instructions, 15=Data Above Normal, Least severe, 16=Data Above Normal, Moder. severe, 17=Data Below Normal, Least Severe, 18=Data Below Normal, Moder. severe, 19=Received Network Data In Error, 20=Data Drifted High, 21=Data Drifted Low, 31=Condition Exists; unit binary}, range phys 0..31, unit=binary
          signal Oc09: start 296, 7 bit, little-endian, data-type-policy=OVERRIDE, init-value=0, base-type=Oc09_Coding, compu {127=Not Available; unit binary}, range phys 0..127, unit=binary
          signal SpnCm09: start 303, 1 bit, little-endian, data-type-policy=OVERRIDE, init-value=0, base-type=SpnCm09_Coding, compu {0=SPN v.4, 1=SPN v.1,2,3}, range phys 0..1
          signal Spn10: start 304, 16 bit, little-endian, data-type-policy=OVERRIDE, init-value=0, base-type=Spn10_Coding, compu {identical; unit binary}, range phys 0..65535, unit=binary
          signal SpnHigh10: start 325, 3 bit, little-endian, data-type-policy=OVERRIDE, init-value=0, base-type=SpnHigh10_Coding, compu {identical; unit binary}, range phys 0..7, unit=binary
          signal Fmi10: start 320, 5 bit, little-endian, data-type-policy=OVERRIDE, init-value=0, base-type=Fmi10_Coding, compu {0=Data Above Normal, Most severe, 1=Data Below Normal, Most severe, 2=Data erratic, interm, incorrect, 3=Voltage above normal, SC High, 4=Voltage below normal, SC Low, 5=Current below normal, OC, 6=Current above normal, SC, 7=Mech. system not responding, 8=Abnormal Freq, Width, Period, 9=Abnormal Update Rate, 10=Abnormal Rate Of Change, 11=Root Cause Not Known, 12=Bad Intell. Device, Component, 13=Out Of Calibration, 14=Special Instructions, 15=Data Above Normal, Least severe, 16=Data Above Normal, Moder. severe, 17=Data Below Normal, Least Severe, 18=Data Below Normal, Moder. severe, 19=Received Network Data In Error, 20=Data Drifted High, 21=Data Drifted Low, 31=Condition Exists; unit binary}, range phys 0..31, unit=binary
          signal Oc10: start 328, 7 bit, little-endian, data-type-policy=OVERRIDE, init-value=0, base-type=Oc10_Coding, compu {127=Not Available; unit binary}, range phys 0..127, unit=binary
          signal SpnCm10: start 335, 1 bit, little-endian, data-type-policy=OVERRIDE, init-value=0, base-type=SpnCm10_Coding, compu {0=SPN v.4, 1=SPN v.1,2,3}, range phys 0..1
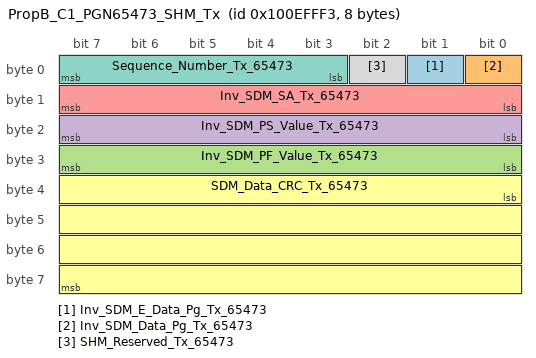
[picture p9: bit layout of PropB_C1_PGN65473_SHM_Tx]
      frame PropB_C1_PGN65473_SHM_Tx: id 0x100EFFF3, from VIC, to Vehicle_Control_Unit, frame-length=8, can-addressing-mode=EXTENDED  # Custom PGN
        pdu PropB_C1_PGN65473_SHM_Tx: length=8, transmission-mode-condition{data-filter=data-filter-type=ALWAYS, i-signal-in-i-pdu=PropB_C1_PGN65473_SHM_Tx_Inv_SDM_E_Data_Pg_Tx_65473}, transmission-mode-true-timing=cyclic-timing=time-period=0.1
          signal Inv_SDM_E_Data_Pg_Tx_65473: start 1, 1 bit, little-endian, data-type-policy=OVERRIDE, init-value=0, base-type=Inv_SDM_E_Data_Pg_Tx_65473_Coding, compu {identical}, range phys 0..1, to Vehicle_Control_Unit
          signal Inv_SDM_Data_Pg_Tx_65473: start 0, 1 bit, little-endian, data-type-policy=OVERRIDE, init-value=0, base-type=Inv_SDM_Data_Pg_Tx_65473_Coding, compu {identical}, range phys 0..1, to Vehicle_Control_Unit
          signal Inv_SDM_PF_Value_Tx_65473: start 24, 8 bit, little-endian, data-type-policy=OVERRIDE, init-value=0, base-type=Inv_SDM_PF_Value_Tx_65473_Coding, compu {identical}, range phys 0..255, to Vehicle_Control_Unit
          signal Inv_SDM_PS_Value_Tx_65473: start 16, 8 bit, little-endian, data-type-policy=OVERRIDE, init-value=0, base-type=Inv_SDM_PS_Value_Tx_65473_Coding, compu {identical}, range phys 0..255, to Vehicle_Control_Unit
          signal Inv_SDM_SA_Tx_65473: start 8, 8 bit, little-endian, data-type-policy=OVERRIDE, init-value=0, base-type=Inv_SDM_SA_Tx_65473_Coding, compu {identical}, range phys 0..255, to Vehicle_Control_Unit
          signal SDM_Data_CRC_Tx_65473: start 32, 32 bit, little-endian, data-type-policy=OVERRIDE, init-value=0, base-type=SDM_Data_CRC_Tx_65473_Coding, compu {identical}, range phys 0..4294967295, to Vehicle_Control_Unit  # data integrity as the measure for message corruption communication errors. (Ref. J1939-76)
          signal Sequence_Number_Tx_65473: start 3, 5 bit, little-endian, data-type-policy=OVERRIDE, init-value=0, base-type=Sequence_Number_Tx_65473_Coding, compu {identical}, range phys 0..31, to Vehicle_Control_Unit  # sequence number increases by 1 for each transmission. (Ref. J1939-76)
          signal SHM_Reserved_Tx_65473: start 2, 1 bit, little-endian, data-type-policy=OVERRIDE, init-value=0, base-type=SHM_Reserved_Tx_65473_Coding, compu {identical}, range phys 0..1, to Vehicle_Control_Unit
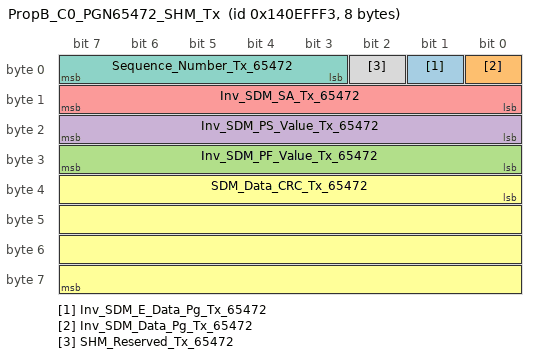
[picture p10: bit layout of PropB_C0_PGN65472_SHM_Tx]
      frame PropB_C0_PGN65472_SHM_Tx: id 0x140EFFF3, from VIC, to Vehicle_Control_Unit, frame-length=8, can-addressing-mode=EXTENDED  # High Voltage Energy Storage System Control 1
        pdu PropB_C0_PGN65472_SHM_Tx: length=8, transmission-mode-condition{data-filter=data-filter-type=ALWAYS, i-signal-in-i-pdu=PropB_C0_PGN65472_SHM_Tx_Inv_SDM_E_Data_Pg_Tx_65472}, transmission-mode-true-timing=cyclic-timing=time-period=0.1
          signal Inv_SDM_E_Data_Pg_Tx_65472: start 1, 1 bit, little-endian, data-type-policy=OVERRIDE, init-value=0, base-type=Inv_SDM_E_Data_Pg_Tx_65472_Coding, compu {identical}, range phys 0..1, to Vehicle_Control_Unit
          signal Inv_SDM_Data_Pg_Tx_65472: start 0, 1 bit, little-endian, data-type-policy=OVERRIDE, init-value=0, base-type=Inv_SDM_Data_Pg_Tx_65472_Coding, compu {identical}, range phys 0..1, to Vehicle_Control_Unit
          signal Inv_SDM_PF_Value_Tx_65472: start 24, 8 bit, little-endian, data-type-policy=OVERRIDE, init-value=0, base-type=Inv_SDM_PF_Value_Tx_65472_Coding, compu {identical}, range phys 0..255, to Vehicle_Control_Unit
          signal Inv_SDM_PS_Value_Tx_65472: start 16, 8 bit, little-endian, data-type-policy=OVERRIDE, init-value=0, base-type=Inv_SDM_PS_Value_Tx_65472_Coding, compu {identical}, range phys 0..255, to Vehicle_Control_Unit
          signal Inv_SDM_SA_Tx_65472: start 8, 8 bit, little-endian, data-type-policy=OVERRIDE, init-value=0, base-type=Inv_SDM_SA_Tx_65472_Coding, compu {identical}, range phys 0..255, to Vehicle_Control_Unit
          signal SDM_Data_CRC_Tx_65472: start 32, 32 bit, little-endian, data-type-policy=OVERRIDE, init-value=0, base-type=SDM_Data_CRC_Tx_65472_Coding, compu {identical}, range phys 0..4294967295, to Vehicle_Control_Unit  # data integrity as the measure for message corruption communication errors. (Ref. J1939-76)
          signal Sequence_Number_Tx_65472: start 3, 5 bit, little-endian, data-type-policy=OVERRIDE, init-value=0, base-type=Sequence_Number_Tx_65472_Coding, compu {identical}, range phys 0..31, to Vehicle_Control_Unit  # sequence number increases by 1 for each transmission. (Ref. J1939-76)
          signal SHM_Reserved_Tx_65472: start 2, 1 bit, little-endian, data-type-policy=OVERRIDE, init-value=0, base-type=SHM_Reserved_Tx_65472_Coding, compu {identical}, range phys 0..1, to Vehicle_Control_Unit
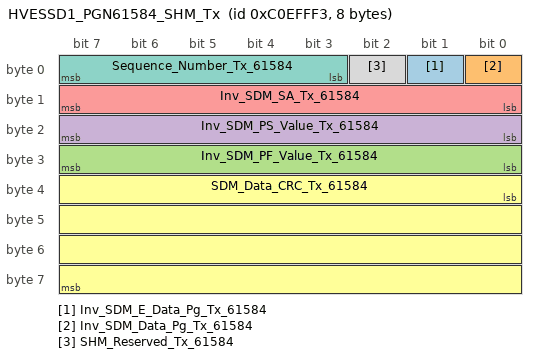
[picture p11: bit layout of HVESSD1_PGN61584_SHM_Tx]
      frame HVESSD1_PGN61584_SHM_Tx: id 0xC0EFFF3, from VIC, to Vehicle_Control_Unit, frame-length=8, can-addressing-mode=EXTENDED  # High Voltage Energy Storage System Control 1
        pdu HVESSD1_PGN61584_SHM_Tx: length=8, transmission-mode-condition{data-filter=data-filter-type=ALWAYS, i-signal-in-i-pdu=HVESSD1_PGN61584_SHM_Tx_Inv_SDM_E_Data_Pg_Tx_61584}, transmission-mode-true-timing=cyclic-timing=time-period=0.02
          signal Inv_SDM_E_Data_Pg_Tx_61584: start 1, 1 bit, little-endian, data-type-policy=OVERRIDE, init-value=0, base-type=Inv_SDM_E_Data_Pg_Tx_61584_Coding, compu {identical}, range phys 0..1, to Vehicle_Control_Unit
          signal Inv_SDM_Data_Pg_Tx_61584: start 0, 1 bit, little-endian, data-type-policy=OVERRIDE, init-value=0, base-type=Inv_SDM_Data_Pg_Tx_61584_Coding, compu {identical}, range phys 0..1, to Vehicle_Control_Unit
          signal Inv_SDM_PF_Value_Tx_61584: start 24, 8 bit, little-endian, data-type-policy=OVERRIDE, init-value=0, base-type=Inv_SDM_PF_Value_Tx_61584_Coding, compu {identical}, range phys 0..255, to Vehicle_Control_Unit
          signal Inv_SDM_PS_Value_Tx_61584: start 16, 8 bit, little-endian, data-type-policy=OVERRIDE, init-value=0, base-type=Inv_SDM_PS_Value_Tx_61584_Coding, compu {identical}, range phys 0..255, to Vehicle_Control_Unit
          signal Inv_SDM_SA_Tx_61584: start 8, 8 bit, little-endian, data-type-policy=OVERRIDE, init-value=0, base-type=Inv_SDM_SA_Tx_61584_Coding, compu {identical}, range phys 0..255, to Vehicle_Control_Unit
          signal SDM_Data_CRC_Tx_61584: start 32, 32 bit, little-endian, data-type-policy=OVERRIDE, init-value=0, base-type=SDM_Data_CRC_Tx_61584_Coding, compu {identical}, range phys 0..4294967295, to Vehicle_Control_Unit  # data integrity as the measure for message corruption communication errors. (Ref. J1939-76)
          signal Sequence_Number_Tx_61584: start 3, 5 bit, little-endian, data-type-policy=OVERRIDE, init-value=0, base-type=Sequence_Number_Tx_61584_Coding, compu {identical}, range phys 0..31, to Vehicle_Control_Unit  # sequence number increases by 1 for each transmission. (Ref. J1939-76)
          signal SHM_Reserved_Tx_61584: start 2, 1 bit, little-endian, data-type-policy=OVERRIDE, init-value=0, base-type=SHM_Reserved_Tx_61584_Coding, compu {identical}, range phys 0..1, to Vehicle_Control_Unit
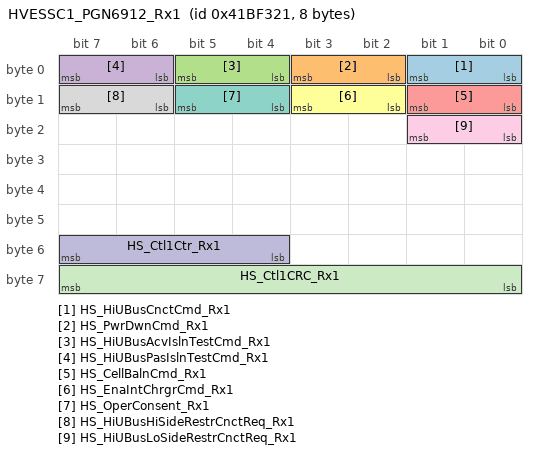
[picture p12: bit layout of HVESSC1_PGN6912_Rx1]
      frame HVESSC1_PGN6912_Rx1: id 0x41BF321, from Vehicle_Control_Unit, to VIC, frame-length=8, can-addressing-mode=EXTENDED  # High Voltage Energy Storage System Control 1
        pdu HVESSC1_PGN6912_Rx1: length=8, transmission-mode-condition{data-filter=data-filter-type=ALWAYS, i-signal-in-i-pdu=HVESSC1_PGN6912_Rx1_HS_HiUBusCnctCmd_Rx1}, transmission-mode-true-timing=cyclic-timing=time-period=0.02
          signal HS_HiUBusCnctCmd_Rx1: start 0, 2 bit, little-endian, data-type-policy=OVERRIDE, init-value=0, base-type=HS_HiUBusCnctCmd_Rx1_Coding, compu {3=11b = Don't care/Take no action, 2=10b = Emergency contactor closure request, 1=01b = Close Contactor; Connect HVES to high-voltage bus, 0=00b = Open Contactor; Disconnect HVES from high-voltage bus; unit bit}, range phys 0..3, unit=bit, to VIC  # Command to connect the High Voltage Energy Storage System (or Pack 1 in systems with only one pack) to the high-voltage bus. The emergency contactor closure request may be used in situations where one or more faults in the hybrid powertrain prevent norm
          signal HS_PwrDwnCmd_Rx1: start 2, 2 bit, little-endian, data-type-policy=OVERRIDE, init-value=0, base-type=HS_PwrDwnCmd_Rx1_Coding, compu {3=11b = Don't care/Take no action, 2=10b = Execute emergency power-down, 1=01b = Execute normal power-down, 0=00b = Power-down not requested; unit bit}, range phys 0..3, unit=bit, to VIC  # Command to shut down the High Voltage Energy Storage System (or Pack 1 in systems with only one pack). A normal power-down may involve steps that take some period of time (tests, writing of data, etc.). However, an emergency power-down should shut down
          signal HS_HiUBusAcvIslnTestCmd_Rx1: start 4, 2 bit, little-endian, data-type-policy=OVERRIDE, init-value=0, base-type=HS_HiUBusAcvIslnTestCmd_Rx1_Coding, compu {3=11b = Don't care/Take no action, 2=10b = Inhibit Active Isolation Test, 1=01b = Active Isolation Test request, 0=00b = Active Isolation Test not requested; unit bit}, range phys 0..3, unit=bit, to VIC  # Command for the High Voltage Energy Storage System (or Pack 1 in systems with only one pack) to perform an active electrical isolation test on the high voltage bus. An active isolation test might use a generated signal (e.g. an injected AC signal) and
          signal HS_HiUBusPasIslnTestCmd_Rx1: start 6, 2 bit, little-endian, data-type-policy=OVERRIDE, init-value=0, base-type=HS_HiUBusPasIslnTestCmd_Rx1_Coding, compu {3=11b = Don't care/Take no action, 2=10b = Inhibit Passive Isolation Test, 1=01b = Passive Isolation Test request, 0=00b = Passive Isolation Test not requested; unit bit}, range phys 0..3, unit=bit, to VIC  # Command for the High Voltage Energy Storage System (or Pack 1 in systems with only one pack) to perform a passive electrical isolation test on the high voltage bus. A passive isolation test uses additional circuitry (e.g. a high impedance network) to
          signal HS_CellBalnCmd_Rx1: start 8, 2 bit, little-endian, data-type-policy=OVERRIDE, init-value=0, base-type=HS_CellBalnCmd_Rx1_Coding, compu {3=11b = Don't care/Take no action, 2=10b = Reserved, 1=01b = Cell Balancing requested, 0=00b = Cell Balancing not requested; unit bit}, range phys 0..3, unit=bit, to VIC  # Command for the High Voltage Energy Storage System (or Pack 1 in systems with only one pack) to perform cell balancing. This parameter provides HVES system level information. If there are multiple packs in the system, then both individual pack message
          signal HS_EnaIntChrgrCmd_Rx1: start 10, 2 bit, little-endian, data-type-policy=OVERRIDE, init-value=0, base-type=HS_EnaIntChrgrCmd_Rx1_Coding, compu {3=11b = Don't care/Take no action, 2=10b = Reserved, 1=01b = Enable charging, 0=00b = Disable charging; unit bit}, range phys 0..3, unit=bit, to VIC  # When the HVES has an internal charger this parameter will enable it. External chargers may use the External Energy Source Connection Demand (SPN 7890) and related SPs. This parameter provides HVES system level information. If there are multiple pack
          signal HS_OperConsent_Rx1: start 12, 2 bit, little-endian, data-type-policy=OVERRIDE, init-value=0, base-type=HS_OperConsent_Rx1_Coding, compu {3=11b = Don't care/Take no action, 2=10b = Error, 1=01b = Consent given; system component consents to HVES instance operation, 0=00b = Consent revoked; system component does not consent to HVES instance operation; unit bit}, range phys 0..3, unit=bit, to VIC  # This parameter provides an indication to the High Voltage Energy Storage System (or Pack 1 in systems with only one pack) that an external device is ready for this HVES instance to proceed with normal operation. In applications which support this parame
          signal HS_HiUBusHiSideRestrCnctReq_Rx1: start 14, 2 bit, little-endian, data-type-policy=OVERRIDE, init-value=0, base-type=HS_HiUBusHiSideRestrCnctReq_Rx1_Coding, compu {3=11b = Don't care/take no action, 2=10b = Reserved, 1=01b = Connection Requested, 0=00b = Connection not Requested; unit bit}, range phys 0..3, unit=bit, to VIC  # This parameter is used to request connection of this HVES instance High-Voltage bus high side resistor in order to perform an isolation test. See also SPN 8434 (HVESS High-Voltage Bus Low Side Resistor Connect Request). This parameter provides HVES
          signal HS_HiUBusLoSideRestrCnctReq_Rx1: start 16, 2 bit, little-endian, data-type-policy=OVERRIDE, init-value=0, base-type=HS_HiUBusLoSideRestrCnctReq_Rx1_Coding, compu {3=11b = Don't care/take no action, 2=10b = Reserved, 1=01b = Connection Requested, 0=00b = Connection not Requested; unit bit}, range phys 0..3, unit=bit, to VIC  # This parameter is used to request connection of this HVES instance High-Voltage bus low side resistor in order to perform an isolation test. See also SPN 8433 (HVESS Low-Voltage Bus High Side Resistor Connect Request). This parameter provides HVES s
          signal HS_Ctl1Ctr_Rx1: start 52, 4 bit, little-endian, data-type-policy=OVERRIDE, init-value=0, base-type=HS_Ctl1Ctr_Rx1_Coding, compu {identical; unit bit}, range phys 0..15, unit=bit, to VIC  # The message counter is used to detect situations where the transmitting ECU malfunction repeats the same frame all the time. The receiver of the information may use the counter parameter to detect this situation. The transmitting device will increase the
          signal HS_Ctl1CRC_Rx1: start 56, 8 bit, little-endian, data-type-policy=OVERRIDE, init-value=0, base-type=HS_Ctl1CRC_Rx1_Coding, compu {identical; unit count}, range phys 0..255, unit=count, to VIC  # The CRC is defined as follows: • Length: 8 bits • Polynomial: x^8+x^5+x^3+x^2+x+1 • Initial Value: FFh • Input Data Reflection: Not reflected • Result Data Reflection: Not reflected • XOR value: FFh SAE makes no claim of the functional saf
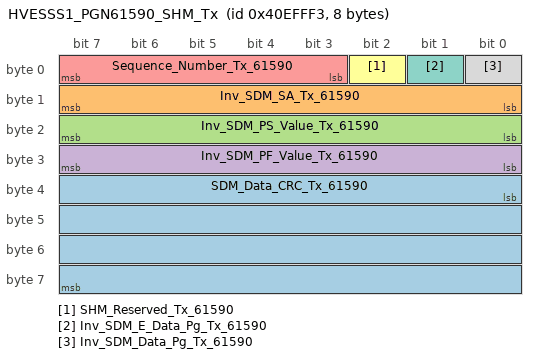
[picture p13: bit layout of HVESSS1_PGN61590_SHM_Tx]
      frame HVESSS1_PGN61590_SHM_Tx: id 0x40EFFF3, from VIC, to Vehicle_Control_Unit, frame-length=8, can-addressing-mode=EXTENDED  # High Voltage Energy Storage System Status 1
        pdu HVESSS1_PGN61590_SHM_Tx: length=8, transmission-mode-condition{data-filter=data-filter-type=ALWAYS, i-signal-in-i-pdu=HVESSS1_PGN61590_SHM_Tx_SDM_Data_CRC_Tx_61590}, transmission-mode-true-timing=cyclic-timing=time-period=0.1
          signal SDM_Data_CRC_Tx_61590: start 32, 32 bit, little-endian, data-type-policy=OVERRIDE, init-value=0, base-type=SDM_Data_CRC_Tx_61590_Coding, compu {identical}, range phys 0..4294967295, to Vehicle_Control_Unit  # data integrity as the measure for message corruption communication errors. (Ref. J1939-76)
          signal Inv_SDM_SA_Tx_61590: start 8, 8 bit, little-endian, data-type-policy=OVERRIDE, init-value=0, base-type=Inv_SDM_SA_Tx_61590_Coding, compu {identical}, range phys 0..255, to Vehicle_Control_Unit
          signal Inv_SDM_PS_Value_Tx_61590: start 16, 8 bit, little-endian, data-type-policy=OVERRIDE, init-value=0, base-type=Inv_SDM_PS_Value_Tx_61590_Coding, compu {identical}, range phys 0..255, to Vehicle_Control_Unit
          signal Inv_SDM_PF_Value_Tx_61590: start 24, 8 bit, little-endian, data-type-policy=OVERRIDE, init-value=0, base-type=Inv_SDM_PF_Value_Tx_61590_Coding, compu {identical}, range phys 0..255, to Vehicle_Control_Unit
          signal Sequence_Number_Tx_61590: start 3, 5 bit, little-endian, data-type-policy=OVERRIDE, init-value=0, base-type=Sequence_Number_Tx_61590_Coding, compu {identical}, range phys 0..31, to Vehicle_Control_Unit  # sequence number increases by 1 for each transmission. (Ref. J1939-76)
          signal SHM_Reserved_Tx_61590: start 2, 1 bit, little-endian, data-type-policy=OVERRIDE, init-value=0, base-type=SHM_Reserved_Tx_61590_Coding, compu {identical}, range phys 0..1, to Vehicle_Control_Unit
          signal Inv_SDM_E_Data_Pg_Tx_61590: start 1, 1 bit, little-endian, data-type-policy=OVERRIDE, init-value=0, base-type=Inv_SDM_E_Data_Pg_Tx_61590_Coding, compu {identical}, range phys 0..1, to Vehicle_Control_Unit
          signal Inv_SDM_Data_Pg_Tx_61590: start 0, 1 bit, little-endian, data-type-policy=OVERRIDE, init-value=0, base-type=Inv_SDM_Data_Pg_Tx_61590_Coding, compu {identical}, range phys 0..1, to Vehicle_Control_Unit
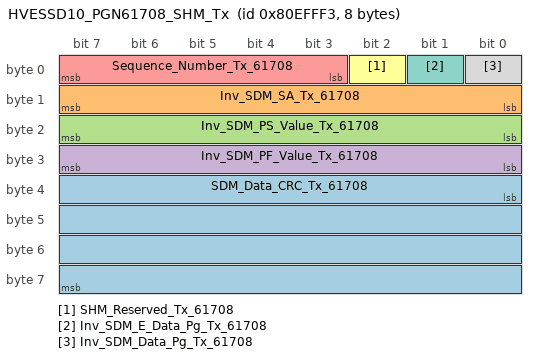
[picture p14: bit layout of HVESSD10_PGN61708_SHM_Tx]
      frame HVESSD10_PGN61708_SHM_Tx: id 0x80EFFF3, from VIC, to Vehicle_Control_Unit, frame-length=8, can-addressing-mode=EXTENDED  # Data set 10 (electrical) for High Voltage Energy Storage System (or Pack 1 in systems with only one pack).
        pdu HVESSD10_PGN61708_SHM_Tx: length=8, transmission-mode-condition{data-filter=data-filter-type=ALWAYS, i-signal-in-i-pdu=HVESSD10_PGN61708_SHM_Tx_SDM_Data_CRC_Tx_61708}, transmission-mode-true-timing=cyclic-timing=time-period=0.1
          signal SDM_Data_CRC_Tx_61708: start 32, 32 bit, little-endian, data-type-policy=OVERRIDE, init-value=0, base-type=SDM_Data_CRC_Tx_61708_Coding, compu {identical}, range phys 0..4294967295, to Vehicle_Control_Unit  # data integrity as the measure for message corruption communication errors. (Ref. J1939-76)
          signal Inv_SDM_SA_Tx_61708: start 8, 8 bit, little-endian, data-type-policy=OVERRIDE, init-value=0, base-type=Inv_SDM_SA_Tx_61708_Coding, compu {identical}, range phys 0..255, to Vehicle_Control_Unit
          signal Inv_SDM_PS_Value_Tx_61708: start 16, 8 bit, little-endian, data-type-policy=OVERRIDE, init-value=0, base-type=Inv_SDM_PS_Value_Tx_61708_Coding, compu {identical}, range phys 0..255, to Vehicle_Control_Unit
          signal Inv_SDM_PF_Value_Tx_61708: start 24, 8 bit, little-endian, data-type-policy=OVERRIDE, init-value=0, base-type=Inv_SDM_PF_Value_Tx_61708_Coding, compu {identical}, range phys 0..255, to Vehicle_Control_Unit
          signal Sequence_Number_Tx_61708: start 3, 5 bit, little-endian, data-type-policy=OVERRIDE, init-value=0, base-type=Sequence_Number_Tx_61708_Coding, compu {identical}, range phys 0..31, to Vehicle_Control_Unit  # sequence number increases by 1 for each transmission. (Ref. J1939-76)
          signal SHM_Reserved_Tx_61708: start 2, 1 bit, little-endian, data-type-policy=OVERRIDE, init-value=0, base-type=SHM_Reserved_Tx_61708_Coding, compu {identical}, range phys 0..1, to Vehicle_Control_Unit
          signal Inv_SDM_E_Data_Pg_Tx_61708: start 1, 1 bit, little-endian, data-type-policy=OVERRIDE, init-value=0, base-type=Inv_SDM_E_Data_Pg_Tx_61708_Coding, compu {identical}, range phys 0..1, to Vehicle_Control_Unit
          signal Inv_SDM_Data_Pg_Tx_61708: start 0, 1 bit, little-endian, data-type-policy=OVERRIDE, init-value=0, base-type=Inv_SDM_Data_Pg_Tx_61708_Coding, compu {identical}, range phys 0..1, to Vehicle_Control_Unit
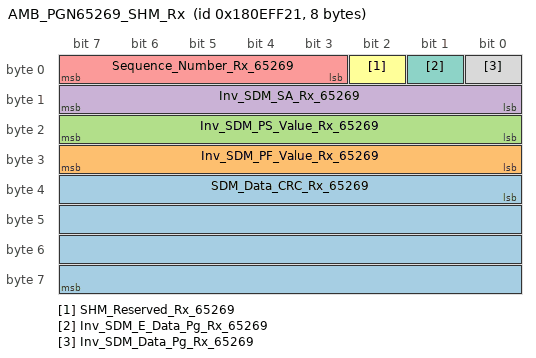
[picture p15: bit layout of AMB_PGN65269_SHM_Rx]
      frame AMB_PGN65269_SHM_Rx: id 0x180EFF21, from Vehicle_Control_Unit, to VIC, frame-length=8, can-addressing-mode=EXTENDED  # Ambient Conditions
        pdu AMB_PGN65269_SHM_Rx: length=8, transmission-mode-condition{data-filter=data-filter-type=ALWAYS, i-signal-in-i-pdu=AMB_PGN65269_SHM_Rx_SDM_Data_CRC_Rx_65269}, transmission-mode-true-timing=cyclic-timing={time-offset=0.2, time-period=1}
          signal SDM_Data_CRC_Rx_65269: start 32, 32 bit, little-endian, data-type-policy=OVERRIDE, init-value=0, base-type=SDM_Data_CRC_Rx_65269_Coding, compu {identical}, range phys 0..4294967295, to VIC  # data integrity as the measure for message corruption communication errors. (Ref. J1939-76)
          signal Inv_SDM_PF_Value_Rx_65269: start 24, 8 bit, little-endian, data-type-policy=OVERRIDE, init-value=0, base-type=Inv_SDM_PF_Value_Rx_65269_Coding, compu {identical}, range phys 0..255, to VIC
          signal Inv_SDM_PS_Value_Rx_65269: start 16, 8 bit, little-endian, data-type-policy=OVERRIDE, init-value=0, base-type=Inv_SDM_PS_Value_Rx_65269_Coding, compu {identical}, range phys 0..255, to VIC
          signal Inv_SDM_SA_Rx_65269: start 8, 8 bit, little-endian, data-type-policy=OVERRIDE, init-value=0, base-type=Inv_SDM_SA_Rx_65269_Coding, compu {identical}, range phys 0..255, to VIC
          signal Sequence_Number_Rx_65269: start 3, 5 bit, little-endian, data-type-policy=OVERRIDE, init-value=0, base-type=Sequence_Number_Rx_65269_Coding, compu {identical}, range phys 0..31, to VIC  # sequence number increases by 1 for each transmission. (Ref. J1939-76)
          signal SHM_Reserved_Rx_65269: start 2, 1 bit, little-endian, data-type-policy=OVERRIDE, init-value=0, base-type=SHM_Reserved_Rx_65269_Coding, compu {identical}, range phys 0..1, to VIC
          signal Inv_SDM_E_Data_Pg_Rx_65269: start 1, 1 bit, little-endian, data-type-policy=OVERRIDE, init-value=0, base-type=Inv_SDM_E_Data_Pg_Rx_65269_Coding, compu {identical}, range phys 0..1, to VIC
          signal Inv_SDM_Data_Pg_Rx_65269: start 0, 1 bit, little-endian, data-type-policy=OVERRIDE, init-value=0, base-type=Inv_SDM_Data_Pg_Rx_65269_Coding, compu {identical}, range phys 0..1, to VIC
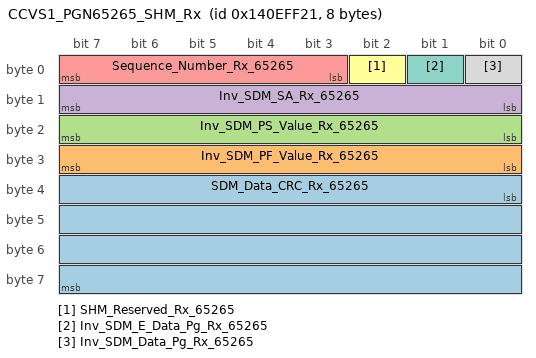
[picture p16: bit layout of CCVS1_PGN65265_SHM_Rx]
      frame CCVS1_PGN65265_SHM_Rx: id 0x140EFF21, from Vehicle_Control_Unit, to VIC, frame-length=8, can-addressing-mode=EXTENDED  # Cruise Control/Vehicle Speed 1
        pdu CCVS1_PGN65265_SHM_Rx: length=8, transmission-mode-condition{data-filter=data-filter-type=ALWAYS, i-signal-in-i-pdu=CCVS1_PGN65265_SHM_Rx_SDM_Data_CRC_Rx_65265}, transmission-mode-true-timing=cyclic-timing={time-offset=0.02, time-period=0.1}
          signal SDM_Data_CRC_Rx_65265: start 32, 32 bit, little-endian, data-type-policy=OVERRIDE, init-value=0, base-type=SDM_Data_CRC_Rx_65265_Coding, compu {identical}, range phys 0..4294967295, to VIC  # data integrity as the measure for message corruption communication errors. (Ref. J1939-76)
          signal Inv_SDM_PF_Value_Rx_65265: start 24, 8 bit, little-endian, data-type-policy=OVERRIDE, init-value=0, base-type=Inv_SDM_PF_Value_Rx_65265_Coding, compu {identical}, range phys 0..255, to VIC
          signal Inv_SDM_PS_Value_Rx_65265: start 16, 8 bit, little-endian, data-type-policy=OVERRIDE, init-value=0, base-type=Inv_SDM_PS_Value_Rx_65265_Coding, compu {identical}, range phys 0..255, to VIC
          signal Inv_SDM_SA_Rx_65265: start 8, 8 bit, little-endian, data-type-policy=OVERRIDE, init-value=0, base-type=Inv_SDM_SA_Rx_65265_Coding, compu {identical}, range phys 0..255, to VIC
          signal Sequence_Number_Rx_65265: start 3, 5 bit, little-endian, data-type-policy=OVERRIDE, init-value=0, base-type=Sequence_Number_Rx_65265_Coding, compu {identical}, range phys 0..31, to VIC  # sequence number increases by 1 for each transmission. (Ref. J1939-76)
          signal SHM_Reserved_Rx_65265: start 2, 1 bit, little-endian, data-type-policy=OVERRIDE, init-value=0, base-type=SHM_Reserved_Rx_65265_Coding, compu {identical}, range phys 0..1, to VIC
          signal Inv_SDM_E_Data_Pg_Rx_65265: start 1, 1 bit, little-endian, data-type-policy=OVERRIDE, init-value=0, base-type=Inv_SDM_E_Data_Pg_Rx_65265_Coding, compu {identical}, range phys 0..1, to VIC
          signal Inv_SDM_Data_Pg_Rx_65265: start 0, 1 bit, little-endian, data-type-policy=OVERRIDE, init-value=0, base-type=Inv_SDM_Data_Pg_Rx_65265_Coding, compu {identical}, range phys 0..1, to VIC
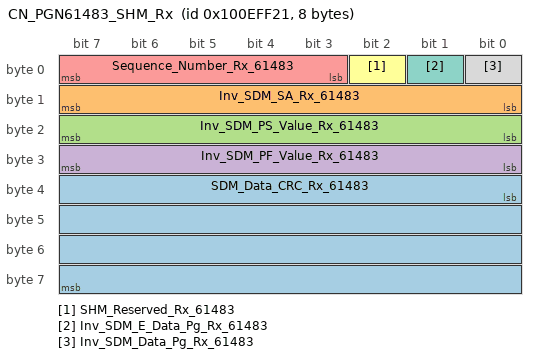
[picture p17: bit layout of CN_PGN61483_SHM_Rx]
      frame CN_PGN61483_SHM_Rx: id 0x100EFF21, from Vehicle_Control_Unit, to VIC, frame-length=8, can-addressing-mode=EXTENDED  # <<Devices developed to the standard published after June 2019 will transmit this message at a rate of 500 ms. Additionally, these devices will also transmit this message every 20 ms for at least 3 s when a crash is detected.>> J1939DA
        pdu CN_PGN61483_SHM_Rx: length=8, transmission-mode-condition{data-filter=data-filter-type=ALWAYS, i-signal-in-i-pdu=CN_PGN61483_SHM_Rx_SDM_Data_CRC_Rx_61483}, transmission-mode-true-timing=cyclic-timing={time-offset=0.004, time-period=0.02}
          signal SDM_Data_CRC_Rx_61483: start 32, 32 bit, little-endian, data-type-policy=OVERRIDE, init-value=0, base-type=SDM_Data_CRC_Rx_61483_Coding, compu {identical}, range phys 0..4294967295, to VIC  # data integrity as the measure for message corruption communication errors. (Ref. J1939-76)
          signal Inv_SDM_SA_Rx_61483: start 8, 8 bit, little-endian, data-type-policy=OVERRIDE, init-value=0, base-type=Inv_SDM_SA_Rx_61483_Coding, compu {identical}, range phys 0..255, to VIC
          signal Inv_SDM_PS_Value_Rx_61483: start 16, 8 bit, little-endian, data-type-policy=OVERRIDE, init-value=0, base-type=Inv_SDM_PS_Value_Rx_61483_Coding, compu {identical}, range phys 0..255, to VIC
          signal Inv_SDM_PF_Value_Rx_61483: start 24, 8 bit, little-endian, data-type-policy=OVERRIDE, init-value=0, base-type=Inv_SDM_PF_Value_Rx_61483_Coding, compu {identical}, range phys 0..255, to VIC
          signal Sequence_Number_Rx_61483: start 3, 5 bit, little-endian, data-type-policy=OVERRIDE, init-value=0, base-type=Sequence_Number_Rx_61483_Coding, compu {identical}, range phys 0..31, to VIC  # sequence number increases by 1 for each transmission. (Ref. J1939-76)
          signal SHM_Reserved_Rx_61483: start 2, 1 bit, little-endian, data-type-policy=OVERRIDE, init-value=0, base-type=SHM_Reserved_Rx_61483_Coding, compu {identical}, range phys 0..1, to VIC
          signal Inv_SDM_E_Data_Pg_Rx_61483: start 1, 1 bit, little-endian, data-type-policy=OVERRIDE, init-value=0, base-type=Inv_SDM_E_Data_Pg_Rx_61483_Coding, compu {identical}, range phys 0..1, to VIC
          signal Inv_SDM_Data_Pg_Rx_61483: start 0, 1 bit, little-endian, data-type-policy=OVERRIDE, init-value=0, base-type=Inv_SDM_Data_Pg_Rx_61483_Coding, compu {identical}, range phys 0..1, to VIC
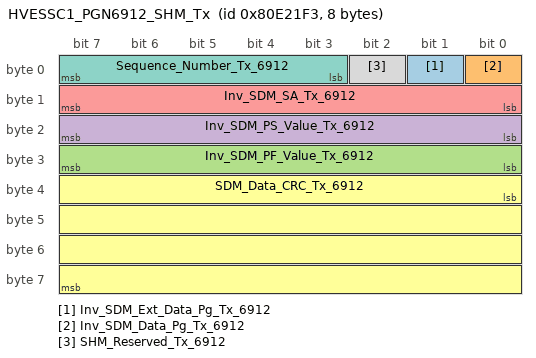
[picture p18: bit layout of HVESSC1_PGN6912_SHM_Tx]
      frame HVESSC1_PGN6912_SHM_Tx: id 0x80E21F3, from VIC, to Vehicle_Control_Unit, frame-length=8, can-addressing-mode=EXTENDED  # High Voltage Energy Storage System Control 1
        pdu HVESSC1_PGN6912_SHM_Tx: length=8, transmission-mode-condition{data-filter=data-filter-type=ALWAYS, i-signal-in-i-pdu=HVESSC1_PGN6912_SHM_Tx_Inv_SDM_Ext_Data_Pg_Tx_6912}, transmission-mode-true-timing=cyclic-timing=time-period=0.02
          signal Inv_SDM_Ext_Data_Pg_Tx_6912: start 1, 1 bit, little-endian, data-type-policy=OVERRIDE, init-value=0, base-type=Inv_SDM_Ext_Data_Pg_Tx_6912_Coding, compu {identical}, range phys 0..1, to Vehicle_Control_Unit
          signal Inv_SDM_Data_Pg_Tx_6912: start 0, 1 bit, little-endian, data-type-policy=OVERRIDE, init-value=0, base-type=Inv_SDM_Data_Pg_Tx_6912_Coding, compu {identical}, range phys 0..1, to Vehicle_Control_Unit
          signal Inv_SDM_PF_Value_Tx_6912: start 24, 8 bit, little-endian, data-type-policy=OVERRIDE, init-value=0, base-type=Inv_SDM_PF_Value_Tx_6912_Coding, compu {identical}, range phys 0..255, to Vehicle_Control_Unit
          signal Inv_SDM_PS_Value_Tx_6912: start 16, 8 bit, little-endian, data-type-policy=OVERRIDE, init-value=0, base-type=Inv_SDM_PS_Value_Tx_6912_Coding, compu {identical}, range phys 0..255, to Vehicle_Control_Unit
          signal Inv_SDM_SA_Tx_6912: start 8, 8 bit, little-endian, data-type-policy=OVERRIDE, init-value=0, base-type=Inv_SDM_SA_Tx_6912_Coding, compu {identical}, range phys 0..255, to Vehicle_Control_Unit
          signal SDM_Data_CRC_Tx_6912: start 32, 32 bit, little-endian, data-type-policy=OVERRIDE, init-value=0, base-type=SDM_Data_CRC_Tx_6912_Coding, compu {identical}, range phys 0..4294967295, to Vehicle_Control_Unit  # data integrity as the measure for message corruption communication errors. (Ref. J1939-76)
          signal Sequence_Number_Tx_6912: start 3, 5 bit, little-endian, data-type-policy=OVERRIDE, init-value=0, base-type=Sequence_Number_Tx_6912_Coding, compu {identical}, range phys 0..31, to Vehicle_Control_Unit  # sequence number increases by 1 for each transmission. (Ref. J1939-76)
          signal SHM_Reserved_Tx_6912: start 2, 1 bit, little-endian, data-type-policy=OVERRIDE, init-value=0, base-type=SHM_Reserved_Tx_6912_Coding, compu {identical}, range phys 0..1, to Vehicle_Control_Unit
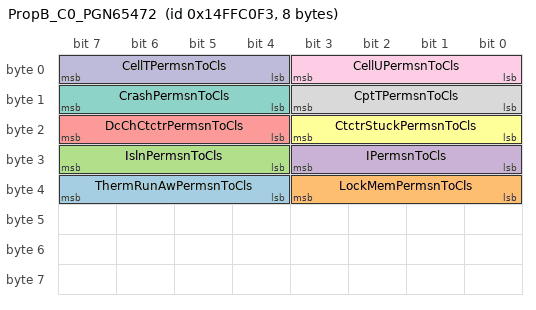
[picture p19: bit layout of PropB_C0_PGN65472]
      frame PropB_C0_PGN65472: id 0x14FFC0F3, from VIC, to Vehicle_Control_Unit, frame-length=8, can-addressing-mode=EXTENDED
        pdu PropB_C0_PGN65472: length=8, transmission-mode-condition{data-filter=data-filter-type=ALWAYS, i-signal-in-i-pdu=PropB_C0_PGN65472_ThermRunAwPermsnToCls}, transmission-mode-true-timing=cyclic-timing=time-period=0.1
          signal ThermRunAwPermsnToCls: start 36, 4 bit, little-endian, data-type-policy=OVERRIDE, init-value=0, base-type=ThermRunAwPermsnToCls_Coding, compu {15=1111b = Info not available (default), 11=1011b = Granted but error, 10=1010b = Granted, 2=10b = Denied permanently, 1=01b = Denied until restart, 0=00b = Denied due to initialization}, range phys 0..15, to Vehicle_Control_Unit
          signal LockMemPermsnToCls: start 32, 4 bit, little-endian, data-type-policy=OVERRIDE, init-value=0, base-type=LockMemPermsnToCls_Coding, compu {15=1111b = Info not available (default), 11=1011b = Granted but error, 10=1010b = Granted, 2=10b = Denied permanently, 1=01b = Denied until restart, 0=00b = Denied due to initialization}, range phys 0..15, to Vehicle_Control_Unit
          signal IslnPermsnToCls: start 28, 4 bit, little-endian, data-type-policy=OVERRIDE, init-value=0, base-type=IslnPermsnToCls_Coding, compu {15=1111b = Info not available (default), 11=1011b = Granted but error, 10=1010b = Granted, 2=10b = Denied permanently, 1=01b = Denied until restart, 0=00b = Denied due to initialization}, range phys 0..15, to Vehicle_Control_Unit
          signal IPermsnToCls: start 24, 4 bit, little-endian, data-type-policy=OVERRIDE, init-value=0, base-type=IPermsnToCls_Coding, compu {15=1111b = Info not available (default), 11=1011b = Granted but error, 10=1010b = Granted, 2=10b = Denied permanently, 1=01b = Denied until restart, 0=00b = Denied due to initialization}, range phys 0..15, to Vehicle_Control_Unit
          signal DcChCtctrPermsnToCls: start 20, 4 bit, little-endian, data-type-policy=OVERRIDE, init-value=0, base-type=DcChCtctrPermsnToCls_Coding, compu {15=1111b = Info not available (default), 11=1011b = Granted but error, 10=1010b = Granted, 2=10b = Denied permanently, 1=01b = Denied until restart, 0=00b = Denied due to initialization}, range phys 0..15, to Vehicle_Control_Unit
          signal CtctrStuckPermsnToCls: start 16, 4 bit, little-endian, data-type-policy=OVERRIDE, init-value=0, base-type=CtctrStuckPermsnToCls_Coding, compu {15=1111b = Info not available (default), 11=1011b = Granted but error, 10=1010b = Granted, 2=10b = Denied permanently, 1=01b = Denied until restart, 0=00b = Denied due to initialization}, range phys 0..15, to Vehicle_Control_Unit
          signal CrashPermsnToCls: start 12, 4 bit, little-endian, data-type-policy=OVERRIDE, init-value=0, base-type=CrashPermsnToCls_Coding, compu {15=1111b = Info not available (default), 11=1011b = Granted but error, 10=1010b = Granted, 2=10b = Denied permanently, 1=01b = Denied until restart, 0=00b = Denied due to initialization}, range phys 0..15, to Vehicle_Control_Unit
          signal CptTPermsnToCls: start 8, 4 bit, little-endian, data-type-policy=OVERRIDE, init-value=0, base-type=CptTPermsnToCls_Coding, compu {15=1111b = Info not available (default), 11=1011b = Granted but error, 10=1010b = Granted, 2=10b = Denied permanently, 1=01b = Denied until restart, 0=00b = Denied due to initialization}, range phys 0..15, to Vehicle_Control_Unit
          signal CellUPermsnToCls: start 0, 4 bit, little-endian, data-type-policy=OVERRIDE, init-value=0, base-type=CellUPermsnToCls_Coding, compu {15=1111b = Info not available (default), 11=1011b = Granted but error, 10=1010b = Granted, 2=10b = Denied permanently, 1=01b = Denied until restart, 0=00b = Denied due to initialization}, range phys 0..15, to Vehicle_Control_Unit
          signal CellTPermsnToCls: start 4, 4 bit, little-endian, data-type-policy=OVERRIDE, init-value=0, base-type=CellTPermsnToCls_Coding, compu {15=1111b = Info not available (default), 11=1011b = Granted but error, 10=1010b = Granted, 2=10b = Denied permanently, 1=01b = Denied until restart, 0=00b = Denied due to initialization}, range phys 0..15, to Vehicle_Control_Unit
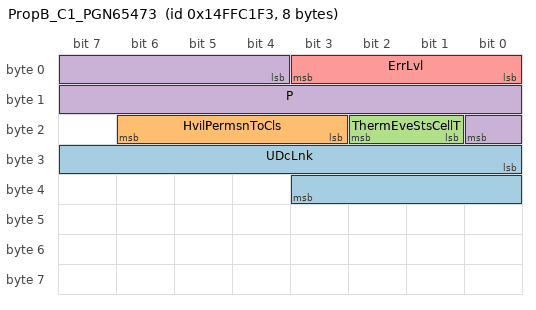
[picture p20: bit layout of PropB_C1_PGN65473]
      frame PropB_C1_PGN65473: id 0x14FFC1F3, from VIC, to Vehicle_Control_Unit, frame-length=8, can-addressing-mode=EXTENDED
        pdu PropB_C1_PGN65473: length=8, transmission-mode-condition{data-filter=data-filter-type=ALWAYS, i-signal-in-i-pdu=PropB_C1_PGN65473_UDcLnk}, transmission-mode-true-timing=cyclic-timing=time-period=0.1
          signal UDcLnk: start 24, 12 bit, little-endian, data-type-policy=OVERRIDE, init-value=0, base-type=UDcLnk_Coding, compu {phys=raw*0.25; unit V}, range phys 0..1023.75, unit=V, to Vehicle_Control_Unit  # DC inlet voltage
          signal HvilPermsnToCls: start 19, 4 bit, little-endian, data-type-policy=OVERRIDE, init-value=0, base-type=HvilPermsnToCls_Coding, compu {15=1111b = Info not available (default), 11=1011b = Granted but error, 10=1010b = Granted, 2=10b = Denied permanently, 1=01b = Denied until restart, 0=00b = Denied due to initialization; unit unit}, range phys 0..15, unit=unit, to Vehicle_Control_Unit
          signal ThermEveStsCellT: start 17, 2 bit, little-endian, data-type-policy=OVERRIDE, init-value=0, base-type=ThermEveStsCellT_Coding, compu {3=11b = info not available (default), 2=10b = crit. temp. warn. limit exceeded, 1=01b = temp. warn. limit exceeded, 0=00b = temperature ok; unit unit}, range phys 0..3, unit=unit, to Vehicle_Control_Unit
          signal P: start 4, 13 bit, little-endian, data-type-policy=OVERRIDE, init-value=0, base-type=P_Coding, compu {phys=raw*0.125; unit kW}, range phys 0..1023.875, unit=kW, to Vehicle_Control_Unit
          signal ErrLvl: start 0, 4 bit, little-endian, data-type-policy=OVERRIDE, init-value=0, base-type=ErrLvl_Coding, compu {7=111b = Open contactors immediately and lock, 6=110b = Open contactors immediately, 5=101b = Open contactors normal, 4=100b = Open contactors with time limit, 3=11b = Open contactors with speed limit, 2=10b = Limp Home with limited power, 1=01b = Internal information, 0=00b = System is ok; unit unit}, range phys 0..7, unit=unit, to Vehicle_Control_Unit
      frame HVESSD2_PGN61585: id 0x1CF091F3, from VIC, to Vehicle_Control_Unit, frame-length=8, can-addressing-mode=EXTENDED  # Data set 2 (electrical data) for High Voltage Energy Storage System (or Pack 1 in systems with only one pack).
        pdu HVESSD2_PGN61585: length=8, transmission-mode-condition{data-filter=data-filter-type=ALWAYS, i-signal-in-i-pdu=HVESSD2_PGN61585_HS_CellVoltDiffStatus}, transmission-mode-true-timing=cyclic-timing=time-period=0.02
          signal HS_CellVoltDiffStatus: start 48, 4 bit, little-endian, data-type-policy=OVERRIDE, init-value=0, base-type=HS_CellVoltDiffStatus_Coding, compu {15=Not Available, 14=Error, 13=Reserved, 12=Reserved, 11=Reserved, 10=Reserved, 9=Reserved, 8=Reserved, 7=Reserved, 6=Reserved, 5=Reserved, 4=Cell-to-cell voltage differential exceeds acceptable limits; it is not known whether balancing can restore battery performance, 3=Cell-to-cell voltage differential exceeds acceptable limits to a point where external maintenance balancing cannot restore battery performance, 2=Cell-to-cell voltage differential exceeds acceptable limits to a point where external maintenance balancing is required to restore battery performance, 1=Cell-to-cel voltage differential exceeds acceptable limits but can be corrected via auto-balancing, 0=Cell-to-cell voltage differential is within acceptable limits}, range phys 0..15, to Vehicle_Control_Unit  # Indicates whether or not the differential between the highest and lowest cell voltages are within acceptable limits, according to the High Voltage Energy Storage System
          signal HS_LowCellVolt: start 32, 16 bit, little-endian, data-type-policy=OVERRIDE, init-value=0, base-type=HS_LowCellVolt_Coding, compu {phys=raw*0.001; unit V}, range phys 0..64.255, unit=V, to Vehicle_Control_Unit  # The lowest voltage level reported by any cell in the High Voltage Energy Storage System (or Pack 1 in systems with only one pack).
          signal HS_HiCellVolt: start 16, 16 bit, little-endian, data-type-policy=OVERRIDE, init-value=0, base-type=HS_HiCellVolt_Coding, compu {phys=raw*0.001; unit V}, range phys 0..64.255, unit=V, to Vehicle_Control_Unit  # IThe highest voltage level reported by any cell in the High Voltage Energy Storage System (or Pack 1 in systems with only one pack).
          signal HS_FastUpdSOC: start 0, 16 bit, little-endian, data-type-policy=OVERRIDE, init-value=0, base-type=HS_FastUpdSOC_Coding, compu {phys=raw/640; unit %}, range phys 0..100.3984375, unit=%, to Vehicle_Control_Unit  # Indicates the High Voltage Energy Storage System (or Pack 1 in systems with only one pack) state of charge. 0% means no charge remaining, 100% means the system is fully charged in terms of physical limits of the energy storage system.
      frame HVESSD10_PGN61708: id 0x14F10CF3, from VIC, to Vehicle_Control_Unit, frame-length=8, can-addressing-mode=EXTENDED  # Data set 10 (electrical) for High Voltage Energy Storage System (or Pack 1 in systems with only one pack).
        pdu HVESSD10_PGN61708: length=8, transmission-mode-condition{data-filter=data-filter-type=ALWAYS, i-signal-in-i-pdu=HVESSD10_PGN61708_HS_HiVoltBusPasIslTR}, transmission-mode-true-timing=cyclic-timing=time-period=0.1
          signal HS_HiVoltBusPasIslTR: start 48, 16 bit, little-endian, data-type-policy=OVERRIDE, init-value=0, base-type=HS_HiVoltBusPasIslTR_Coding, compu {phys=raw*0.1; unit ohm/V}, range phys 0..6425.5, unit=ohm/V, to Vehicle_Control_Unit  # The isolation resistance expressed in Ohms per Volt that resulted from the High-Voltage Bus Passive Isolation Test
          signal HS_HiVoltBusActIslTR: start 32, 16 bit, little-endian, data-type-policy=OVERRIDE, init-value=0, base-type=HS_HiVoltBusActIslTR_Coding, compu {phys=raw*0.1; unit ohm/V}, range phys 0..6425.5, unit=ohm/V, to Vehicle_Control_Unit  # The isolation resistance expressed in Ohms per Volt that resulted from the High-Voltage Bus Active Isolation Test
          signal HS_LowCellSOCCellNum: start 24, 8 bit, little-endian, data-type-policy=OVERRIDE, init-value=0, base-type=HS_LowCellSOCCellNum_Coding, compu {identical; unit count}, range phys 0..250, unit=count, to Vehicle_Control_Unit  # Identifies the location of SPN 8084 (HVESS Lowest Cell State of Charge) within SPN 8247 (HVESS Lowest Cell State of Charge Module Number).
          signal HS_LowCellSOCMNum: start 16, 8 bit, little-endian, data-type-policy=OVERRIDE, init-value=0, base-type=HS_LowCellSOCMNum_Coding, compu {identical; unit count}, range phys 0..250, unit=count, to Vehicle_Control_Unit  # Identifies the location of the module containing SPN 8084 (HVESS Lowest Cell State of Charge).
          signal HS_HiCellSOCCellNum: start 8, 8 bit, little-endian, data-type-policy=OVERRIDE, init-value=0, base-type=HS_HiCellSOCCellNum_Coding, compu {identical; unit count}, range phys 0..250, unit=count, to Vehicle_Control_Unit  # Identifies the location of SPN 8085 (HVESS Highest Cell State of Charge) within SPN 8245 (HVESS Highest Cell State of Charge Module Number).
          signal HS_HiCellSOCMNum: start 0, 8 bit, little-endian, data-type-policy=OVERRIDE, init-value=0, base-type=HS_HiCellSOCMNum_Coding, compu {identical; unit count}, range phys 0..250, unit=count, to Vehicle_Control_Unit  # Identifies the location of the module containing SPN 8085 (HVESS Highest Cell State of Charge).
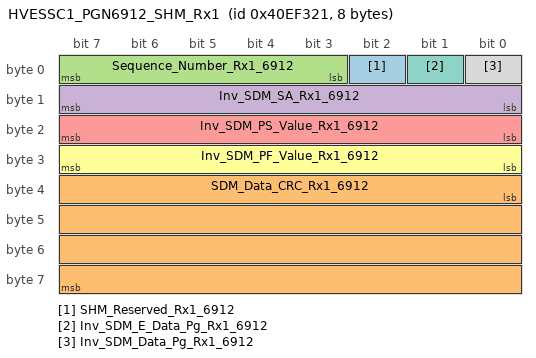
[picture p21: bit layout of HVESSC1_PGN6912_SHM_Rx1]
      frame HVESSC1_PGN6912_SHM_Rx1: id 0x40EF321, from Vehicle_Control_Unit, to VIC, frame-length=8, can-addressing-mode=EXTENDED  # High Voltage Energy Storage System Control 1
        pdu HVESSC1_PGN6912_SHM_Rx1: length=8, transmission-mode-condition{data-filter=data-filter-type=ALWAYS, i-signal-in-i-pdu=HVESSC1_PGN6912_SHM_Rx1_SHM_Reserved_Rx1_6912}, transmission-mode-true-timing=cyclic-timing={time-offset=0.004, time-period=0.02}
          signal SHM_Reserved_Rx1_6912: start 2, 1 bit, little-endian, data-type-policy=OVERRIDE, init-value=0, base-type=SHM_Reserved_Rx1_6912_Coding, compu {identical}, range phys 0..1, to VIC
          signal SDM_Data_CRC_Rx1_6912: start 32, 32 bit, little-endian, data-type-policy=OVERRIDE, init-value=0, base-type=SDM_Data_CRC_Rx1_6912_Coding, compu {identical}, range phys 0..4294967295, to VIC  # data integrity as the measure for message corruption communication errors. (Ref. J1939-76)
          signal Sequence_Number_Rx1_6912: start 3, 5 bit, little-endian, data-type-policy=OVERRIDE, init-value=0, base-type=Sequence_Number_Rx1_6912_Coding, compu {identical}, range phys 0..31, to VIC  # sequence number increases by 1 for each transmission. (Ref. J1939-76)
          signal Inv_SDM_SA_Rx1_6912: start 8, 8 bit, little-endian, data-type-policy=OVERRIDE, init-value=0, base-type=Inv_SDM_SA_Rx1_6912_Coding, compu {identical}, range phys 0..255, to VIC
          signal Inv_SDM_PS_Value_Rx1_6912: start 16, 8 bit, little-endian, data-type-policy=OVERRIDE, init-value=0, base-type=Inv_SDM_PS_Value_Rx1_6912_Coding, compu {identical}, range phys 0..255, to VIC
          signal Inv_SDM_PF_Value_Rx1_6912: start 24, 8 bit, little-endian, data-type-policy=OVERRIDE, init-value=0, base-type=Inv_SDM_PF_Value_Rx1_6912_Coding, compu {identical}, range phys 0..255, to VIC
          signal Inv_SDM_E_Data_Pg_Rx1_6912: start 1, 1 bit, little-endian, data-type-policy=OVERRIDE, init-value=0, base-type=Inv_SDM_E_Data_Pg_Rx1_6912_Coding, compu {identical}, range phys 0..1, to VIC
          signal Inv_SDM_Data_Pg_Rx1_6912: start 0, 1 bit, little-endian, data-type-policy=OVERRIDE, init-value=0, base-type=Inv_SDM_Data_Pg_Rx1_6912_Coding, compu {identical}, range phys 0..1, to VIC
      frame RQST_ES_PGN59904_Rx2: id 0xEAF3EF, from DMU_VEDS, to VIC, frame-length=3, can-addressing-mode=EXTENDED
        pdu RQST_ES_PGN59904_Rx2: length=3
          signal RQST_Rx2: start 0, 24 bit, little-endian, data-type-policy=OVERRIDE, init-value=0, base-type=RQST_Rx2_Coding, compu {identical}, to VIC  # Upon Requset. To be requested every 5 sec , A request should be sent on 59904 PGN and customer has to support the request handling
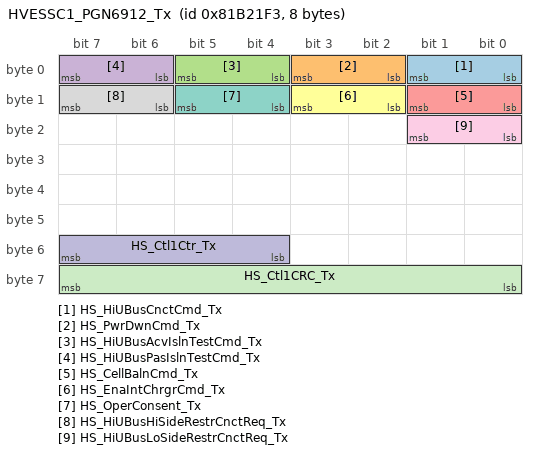
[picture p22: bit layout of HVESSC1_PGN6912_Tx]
      frame HVESSC1_PGN6912_Tx: id 0x81B21F3, from VIC, to Vehicle_Control_Unit, frame-length=8, can-addressing-mode=EXTENDED  # High Voltage Energy Storage System Control 1
        pdu HVESSC1_PGN6912_Tx: length=8, transmission-mode-condition{data-filter=data-filter-type=ALWAYS, i-signal-in-i-pdu=HVESSC1_PGN6912_Tx_HS_HiUBusCnctCmd_Tx}, transmission-mode-true-timing=cyclic-timing=time-period=0.02
          signal HS_HiUBusCnctCmd_Tx: start 0, 2 bit, little-endian, data-type-policy=OVERRIDE, init-value=0, base-type=HS_HiUBusCnctCmd_Tx_Coding, compu {3=11b = Don't care/Take no action, 2=10b = Emergency contactor closure request, 1=01b = Close Contactor; Connect HVES to high-voltage bus, 0=00b = Open Contactor; Disconnect HVES from high-voltage bus; unit bit}, range phys 0..3, unit=bit, to Vehicle_Control_Unit  # Command to connect the High Voltage Energy Storage System (or Pack 1 in systems with only one pack) to the high-voltage bus. The emergency contactor closure request may be used in situations where one or more faults in the hybrid powertrain prevent norm
          signal HS_PwrDwnCmd_Tx: start 2, 2 bit, little-endian, data-type-policy=OVERRIDE, init-value=0, base-type=HS_PwrDwnCmd_Tx_Coding, compu {3=11b = Don't care/Take no action, 2=10b = Execute emergency power-down, 1=01b = Execute normal power-down, 0=00b = Power-down not requested; unit bit}, range phys 0..3, unit=bit, to Vehicle_Control_Unit  # Command to shut down the High Voltage Energy Storage System (or Pack 1 in systems with only one pack). A normal power-down may involve steps that take some period of time (tests, writing of data, etc.). However, an emergency power-down should shut down
          signal HS_HiUBusAcvIslnTestCmd_Tx: start 4, 2 bit, little-endian, data-type-policy=OVERRIDE, init-value=0, base-type=HS_HiUBusAcvIslnTestCmd_Tx_Coding, compu {3=11b = Don't care/Take no action, 2=10b = Inhibit Active Isolation Test, 1=01b = Active Isolation Test request, 0=00b = Active Isolation Test not requested; unit bit}, range phys 0..3, unit=bit, to Vehicle_Control_Unit  # Command for the High Voltage Energy Storage System (or Pack 1 in systems with only one pack) to perform an active electrical isolation test on the high voltage bus. An active isolation test might use a generated signal (e.g. an injected AC signal) and
          signal HS_HiUBusPasIslnTestCmd_Tx: start 6, 2 bit, little-endian, data-type-policy=OVERRIDE, init-value=0, base-type=HS_HiUBusPasIslnTestCmd_Tx_Coding, compu {3=11b = Don't care/Take no action, 2=10b = Inhibit Passive Isolation Test, 1=01b = Passive Isolation Test request, 0=00b = Passive Isolation Test not requested; unit bit}, range phys 0..3, unit=bit, to Vehicle_Control_Unit  # Command for the High Voltage Energy Storage System (or Pack 1 in systems with only one pack) to perform a passive electrical isolation test on the high voltage bus. A passive isolation test uses additional circuitry (e.g. a high impedance network) to
          signal HS_CellBalnCmd_Tx: start 8, 2 bit, little-endian, data-type-policy=OVERRIDE, init-value=0, base-type=HS_CellBalnCmd_Tx_Coding, compu {3=11b = Don't care/Take no action, 2=10b = Reserved, 1=01b = Cell Balancing requested, 0=00b = Cell Balancing not requested; unit bit}, range phys 0..3, unit=bit, to Vehicle_Control_Unit  # Command for the High Voltage Energy Storage System (or Pack 1 in systems with only one pack) to perform cell balancing. This parameter provides HVES system level information. If there are multiple packs in the system, then both individual pack message
          signal HS_EnaIntChrgrCmd_Tx: start 10, 2 bit, little-endian, data-type-policy=OVERRIDE, init-value=0, base-type=HS_EnaIntChrgrCmd_Tx_Coding, compu {3=11b = Don't care/Take no action, 2=10b = Reserved, 1=01b = Enable charging, 0=00b = Disable charging; unit bit}, range phys 0..3, unit=bit, to Vehicle_Control_Unit  # When the HVES has an internal charger this parameter will enable it. External chargers may use the External Energy Source Connection Demand (SPN 7890) and related SPs. This parameter provides HVES system level information. If there are multiple pack
          signal HS_OperConsent_Tx: start 12, 2 bit, little-endian, data-type-policy=OVERRIDE, init-value=0, base-type=HS_OperConsent_Tx_Coding, compu {3=11b = Don't care/Take no action, 2=10b = Error, 1=01b = Consent given; system component consents to HVES instance operation, 0=00b = Consent revoked; system component does not consent to HVES instance operation; unit bit}, range phys 0..3, unit=bit, to Vehicle_Control_Unit  # This parameter provides an indication to the High Voltage Energy Storage System (or Pack 1 in systems with only one pack) that an external device is ready for this HVES instance to proceed with normal operation. In applications which support this parame
          signal HS_HiUBusHiSideRestrCnctReq_Tx: start 14, 2 bit, little-endian, data-type-policy=OVERRIDE, init-value=0, base-type=HS_HiUBusHiSideRestrCnctReq_Tx_Coding, compu {3=11b = Don't care/take no action, 2=10b = Reserved, 1=01b = Connection Requested, 0=00b = Connection not Requested; unit bit}, range phys 0..3, unit=bit, to Vehicle_Control_Unit  # This parameter is used to request connection of this HVES instance High-Voltage bus high side resistor in order to perform an isolation test. See also SPN 8434 (HVESS High-Voltage Bus Low Side Resistor Connect Request). This parameter provides HVES
          signal HS_HiUBusLoSideRestrCnctReq_Tx: start 16, 2 bit, little-endian, data-type-policy=OVERRIDE, init-value=0, base-type=HS_HiUBusLoSideRestrCnctReq_Tx_Coding, compu {3=11b = Don't care/take no action, 2=10b = Reserved, 1=01b = Connection Requested, 0=00b = Connection not Requested; unit bit}, range phys 0..3, unit=bit, to Vehicle_Control_Unit  # This parameter is used to request connection of this HVES instance High-Voltage bus low side resistor in order to perform an isolation test. See also SPN 8433 (HVESS Low-Voltage Bus High Side Resistor Connect Request). This parameter provides HVES s
          signal HS_Ctl1Ctr_Tx: start 52, 4 bit, little-endian, data-type-policy=OVERRIDE, init-value=0, base-type=HS_Ctl1Ctr_Tx_Coding, compu {identical; unit bit}, range phys 0..15, unit=bit, to Vehicle_Control_Unit  # The message counter is used to detect situations where the transmitting ECU malfunction repeats the same frame all the time. The receiver of the information may use the counter parameter to detect this situation. The transmitting device will increase the
          signal HS_Ctl1CRC_Tx: start 56, 8 bit, little-endian, data-type-policy=OVERRIDE, init-value=0, base-type=HS_Ctl1CRC_Tx_Coding, compu {identical; unit count}, range phys 0..255, unit=count, to Vehicle_Control_Unit  # The CRC is defined as follows: • Length: 8 bits • Polynomial: x^8+x^5+x^3+x^2+x+1 • Initial Value: FFh • Input Data Reflection: Not reflected • Result Data Reflection: Not reflected • XOR value: FFh SAE makes no claim of the functional saf
      frame CN_PGN61483: id 0x18F02B21, from Vehicle_Control_Unit, to VIC, frame-length=8, can-addressing-mode=EXTENDED  # <<Devices developed to the standard published after June 2019 will transmit this message at a rate of 500 ms. Additionally, these devices will also transmit this message every 20 ms for at least 3 s when a crash is detected.>> J1939DA
        pdu CN_PGN61483: length=8, transmission-mode-condition{data-filter=data-filter-type=ALWAYS, i-signal-in-i-pdu=CN_PGN61483_Crash_Typ}, transmission-mode-true-timing=cyclic-timing=time-period=0.02
          signal Crash_Typ: start 0, 5 bit, little-endian, data-type-policy=OVERRIDE, init-value=0, base-type=Crash_Typ_Coding, compu {5=00101b = frontal and side (left), 16=10000b = rollover, 8=01000b = side crash (right), 4=00100b = side crash (left), 2=00010b = rear crash, 1=00001b = frontal crash, 0=00000b = no crash; unit bit-mapped}, range phys 0..5, unit=bit-mapped, to VIC  # Type of crash event. 00000b = no crash 00001b = frontal crash 00010b = rear crash 00100b = side crash (left) 01000b = side crash (right) 10000b = rollover It is possible to combine different Crash Types. (e.g. frontal and side crash (left) =
          signal Crash_Ctr: start 56, 4 bit, little-endian, data-type-policy=OVERRIDE, init-value=0, base-type=Crash_Ctr_Coding, compu {identical; unit count}, range phys 0..15, unit=count, to VIC  # The Crash Counter prevents other ECUs from reacting to a faulty transmission of the Crash Notification PG and serves as a safety mechanism. The Crash Counter becomes incremented by 1 for every sent message, and wraps around to 0 when the previously trans
          signal Crash_Cks: start 60, 4 bit, little-endian, data-type-policy=OVERRIDE, init-value=0, base-type=Crash_Cks_Coding, compu {1=Checksum = ((Checksum >> 4) + Checksum) & 0Fh, 0=Checksum = (Byte1 + Byte2 + Byte3 + Byte4 + Byte5 + Byte6 + Byte7 + (message counter & 0Fh) + message ID low byte + message ID mid low byte + message ID mid high byte + message ID high byte); unit count}, range phys 0..15, unit=count, to VIC  # The Crash Checksum is used to verify the signal path from the airbag ECU to other devices in case of a crash. The 4 bit checksum is the sum of the high nibble and the low nibble of the sum of the identifier, the first 7 data bytes and the 4 bit messag
      frame HVESSD1_PGN61584: id 0xCF090F3, from VIC, to Vehicle_Control_Unit, frame-length=8, can-addressing-mode=EXTENDED  # High Voltage Energy Storage System Data 1
        pdu HVESSD1_PGN61584: length=8, transmission-mode-condition{data-filter=data-filter-type=ALWAYS, i-signal-in-i-pdu=HVESSD1_PGN61584_HS_AvlDchaPwr}, transmission-mode-true-timing=cyclic-timing=time-period=0.02
          signal HS_AvlDchaPwr: start 0, 16 bit, little-endian, data-type-policy=OVERRIDE, init-value=0, base-type=HS_AvlDchaPwr_Coding, compu {phys=raw*0.05; unit kW}, range phys 0..3212.75, unit=kW, to Vehicle_Control_Unit  # The rate at which the High Voltage Energy Storage System (or Pack 1 in systems with only one pack) can currently provide energy for propulsion or other uses. This parameter provides HVES system level information. If there are multiple packs in the sys
          signal HS_AvlChPwr: start 16, 16 bit, little-endian, data-type-policy=OVERRIDE, init-value=0, base-type=HS_AvlChPwr_Coding, compu {phys=raw*0.05; unit kW}, range phys 0..3212.75, unit=kW, to Vehicle_Control_Unit  # The rate at which the High Voltage Energy Storage System (or Pack 1 in systems with only one pack) can currently receive energy from a regenerative or recharging system. This parameter provides HVES system level information. If there are multiple pack
          signal HS_ULvl: start 32, 16 bit, little-endian, data-type-policy=OVERRIDE, init-value=0, base-type=HS_ULvl_Coding, compu {phys=raw*0.05; unit V}, range phys 0..3212.75, unit=V, to Vehicle_Control_Unit  # The voltage level of the High Voltage Energy Storage System (or Pack 1 in systems with only one pack). This parameter should be synchronized with SPN 5920 (HVESS Current) such that a realized power value can be calculated. If the HVES component physical
          signal HS_I: start 48, 16 bit, little-endian, data-type-policy=OVERRIDE, init-value=0, base-type=HS_I_Coding, compu {phys=raw*0.05-1600; unit A}, range phys -1600..1612.75, unit=A, to Vehicle_Control_Unit  # The current in or out of the High Voltage Energy Storage System (or Pack 1 in systems with only one pack). This parameter should be synchronized with SPN 5919 (HVESS Voltage Level) such that a realized power value can be calculated. This parameter is de
      frame HVESSD5_PGN61588: id 0x18F094F3, from VIC, to Vehicle_Control_Unit, frame-length=8, can-addressing-mode=EXTENDED  # High Voltage Energy Storage System Data 5
        pdu HVESSD5_PGN61588: length=8, transmission-mode-condition{data-filter=data-filter-type=ALWAYS, i-signal-in-i-pdu=HVESSD5_PGN61588_HS_DchaILim}, transmission-mode-true-timing=cyclic-timing=time-period=0.02
          signal HS_DchaILim: start 0, 16 bit, little-endian, data-type-policy=OVERRIDE, init-value=0, base-type=HS_DchaILim_Coding, compu {phys=raw*0.05-1600; unit A}, range phys -1600..1612.75, unit=A, to Vehicle_Control_Unit  # The maximum permissible current flow out of the High Voltage Energy Storage System (or Pack 1 in systems with only one pack). This parameter is defined from the high voltage energy storage system's point of view. A negative value represents current fl
          signal HS_ChILim: start 16, 16 bit, little-endian, data-type-policy=OVERRIDE, init-value=0, base-type=HS_ChILim_Coding, compu {phys=raw*0.05-1600; unit A}, range phys -1600..1612.75, unit=A, to Vehicle_Control_Unit  # The maximum permissible current flow into the High Voltage Energy Storage System (or Pack 1 in systems with only one pack). This parameter is defined from the high voltage energy storage system's point of view. A positive value represents current flow
          signal HS_MinCellStofCh: start 32, 16 bit, little-endian, data-type-policy=OVERRIDE, init-value=0, base-type=HS_MinCellStofCh_Coding, compu {phys=raw/640; unit %}, range phys 0..100.3984375, unit=%, to Vehicle_Control_Unit  # Indicates the state of charge of the lowest-charged cell in the High Voltage Energy Storage System (or Pack 1 in systems with only one pack). 0% means no charge remaining, 100% means the cell is fully charged. If a single state of charge value covers
          signal HS_MaxCellStofCh: start 48, 16 bit, little-endian, data-type-policy=OVERRIDE, init-value=0, base-type=HS_MaxCellStofCh_Coding, compu {phys=raw/640; unit %}, range phys 0..100.3984375, unit=%, to Vehicle_Control_Unit  # Indicates the state of charge of the highest-charged cell in the High Voltage Energy Storage System (or Pack 1 in systems with only one pack). 0% means no charge remaining, 100% means the cell is fully charged. If a single state of charge value covers
      frame HVESSS1_PGN61590: id 0x14F096F3, from VIC, to Vehicle_Control_Unit, frame-length=8, can-addressing-mode=EXTENDED  # High Voltage Energy Storage System Status 1
        pdu HVESSS1_PGN61590: length=8, transmission-mode-condition{data-filter=data-filter-type=ALWAYS, i-signal-in-i-pdu=HVESSS1_PGN61590_HS_HiUBusPosCtctrSt}, transmission-mode-true-timing=cyclic-timing=time-period=0.1
          signal HS_HiUBusPosCtctrSt: start 0, 2 bit, little-endian, data-type-policy=OVERRIDE, init-value=0, base-type=HS_HiUBusPosCtctrSt_Coding, compu {3=11b = Not Available, 2=10b = Error, 1=01b = Contactor Closed, 0=00b = Contactor Open; unit bit}, range phys 0..3, unit=bit, to Vehicle_Control_Unit  # Position of the High Voltage Energy Storage System (or Pack 1 in systems with only one pack) positive side bus contactor. When this contactor is closed, the positive side of this HVES instance is connected to the positive side of the high-voltage bus.
          signal HS_HiUBusNegCtctrSt: start 2, 2 bit, little-endian, data-type-policy=OVERRIDE, init-value=0, base-type=HS_HiUBusNegCtctrSt_Coding, compu {3=11b = Not Available, 2=10b = Error, 1=01b = Contactor Closed, 0=00b = Contactor Open; unit bit}, range phys 0..3, unit=bit, to Vehicle_Control_Unit  # Position of the High Voltage Energy Storage System (or Pack 1 in systems with only one pack) negative side bus contactor. When this contactor is closed, the negative side of this HVES instance is connected to the negative side of the high-voltage bus.
          signal HS_HiUBusDcnctForewarning: start 4, 4 bit, little-endian, data-type-policy=OVERRIDE, init-value=0, base-type=HS_HiUBusDcnctForewarning_Coding, compu {15=1111b = Not Available, 14=1110b = Error, 13=1101b = Disconnect imminent - no reason given, 12=1100b = Reserved, 11=1011b = Reserved, 10=1010b = Reserved, 9=1001b = Reserved, 8=1000b = Reserved, 7=0111b = Disconnect imminent due to battery pack current approaching maximum acceptable level, 6=0110b = Disconnect imminent due to cell voltage approaching maximum acceptable level, 5=0101b = Disconnect imminent due to cell voltage approaching minimum acceptable level, 4=0100b = Disconnect imminent due to module voltage approaching maximum acceptable level, 3=0011b = Disconnect imminent due to module voltage approaching minimum acceptable level, 2=0010b = Disconnect imminent due to battery pack voltage approaching maximum acceptable level, 1=0001b = Disconnect imminent due to battery pack voltage approaching minimum acceptable level, 0=0000b = Disconnect not pending; unit bit}, range phys 0..15, unit=bit, to Vehicle_Control_Unit  # Indicates that the High Voltage Energy Storage System (or Pack 1 in systems with only one pack) is about to disconnect from the high voltage bus due to unacceptable conditions. This parameter provides HVES system level information. If there are multip
          signal HS_HiUBusPreChRlySt: start 8, 2 bit, little-endian, data-type-policy=OVERRIDE, init-value=0, base-type=HS_HiUBusPreChRlySt_Coding, compu {3=11b = Not Available, 2=10b = Error, 1=01b = Relay Closed, 0=00b = Relay Open; unit bit}, range phys 0..3, unit=bit, to Vehicle_Control_Unit  # Position of the high-voltage bus contactor pre-charge relay. When this relay is closed, the High Voltage Energy Storage System (or Pack 1 in systems with only one pack) is bringing the high-voltage bus up to its operating level. This parameter provid
          signal HS_CentrofPackCtctrSt: start 10, 2 bit, little-endian, data-type-policy=OVERRIDE, init-value=0, base-type=HS_CentrofPackCtctrSt_Coding, compu {3=11b = Not Available, 2=10b = Error, 1=01b = Contactor Closed, 0=00b = Contactor Open; unit bit}, range phys 0..3, unit=bit, to Vehicle_Control_Unit  # Position of the center high-voltage contactor. When this contactor is closed, the positive half of the High Voltage Energy Storage System (or Pack 1 in systems with only one pack) is connected to the negative half. If a system controls the positive, ne
          signal HS_HiUBusAcvIslnTestSts: start 12, 4 bit, little-endian, data-type-policy=OVERRIDE, init-value=0, base-type=HS_HiUBusAcvIslnTestSts_Coding, compu {15=1111b = Not available, 14=1110b = Error, 13=1101b = Reserved, 12=1100b = Reserved, 11=1011b = Reserved, 10=1010b = Reserved, 9=1001b = Reserved, 8=1000b = Reserved, 7=0111b = Reserved, 6=0110b = Test is inhibited, 5=0101b = Test complete; isolation fault, 4=0100b = Test complete; isolation marginal, 3=0011b = Test complete; isolation acceptable, 2=0010b = Test in process, 1=0001b = Test requested but not yet in process, 0=0000b = No test requested / No test in process; unit bit}, range phys 0..15, unit=bit, to Vehicle_Control_Unit  # Status of the high-voltage bus electrical active isolation test as performed by the High Voltage Energy Storage System (or Pack 1 in systems with only one pack). This parameter provides HVES system level information. If there are multiple packs in the
          signal HS_HiUBusPasIslnTestSts: start 16, 4 bit, little-endian, data-type-policy=OVERRIDE, init-value=0, base-type=HS_HiUBusPasIslnTestSts_Coding, compu {15=1111b = Not available, 14=1110b = Error, 13=1101b = Reserved, 12=1100b = Reserved, 11=1011b = Reserved, 10=1010b = Reserved, 9=1001b = Reserved, 8=1000b = Reserved, 7=0111b = Reserved, 6=0110b = Test is inhibited, 5=0101b = Test complete; isolation fault, 4=0100b = Test complete; isolation marginal, 3=0011b = Test complete; isolation acceptable, 2=0010b = Test in process, 1=0001b = Test requested but not yet in process, 0=0000b = No test requested / No test in process; unit bit}, range phys 0..15, unit=bit, to Vehicle_Control_Unit  # Status of the high-voltage bus electrical passive isolation test as performed by the High Voltage Energy Storage System (or Pack 1 in systems with only one pack). This parameter provides HVES system level information. If there are multiple packs in th
          signal HS_HVILSts: start 20, 2 bit, little-endian, data-type-policy=OVERRIDE, init-value=0, base-type=HS_HVILSts_Coding, compu {3=11b = Not Available, 2=10b = Error, 1=01b = HVIL Open, 0=00b = HVIL Closed; unit bit}, range phys 0..3, unit=bit, to Vehicle_Control_Unit  # Status of the High Voltage Interlock Loop from the viewpoint of the High Voltage Energy Storage System (or Pack 1 in systems with only one pack). This parameter provides HVES system level information. If there are multiple packs in the system, then bo
          signal HS_JSwtSts: start 22, 2 bit, little-endian, data-type-policy=OVERRIDE, init-value=0, base-type=HS_JSwtSts_Coding, compu {3=11b = Not Available, 2=10b = Error, 1=01b = Impact sensed, 0=00b = No impact sensed; unit bit}, range phys 0..3, unit=bit, to Vehicle_Control_Unit  # Switch indicating that an impact has been sensed by the High Voltage Energy Storage System (or Pack 1 in systems with only one pack). The impact indication may require action by another controller, or by this HVES instance itself. For example, a control
          signal HS_StofChSts: start 24, 4 bit, little-endian, data-type-policy=OVERRIDE, init-value=0, base-type=HS_StofChSts_Coding, compu {15=1111b = Not Available, 14=1110b = Error, 13=1101b = Reserved, 12=1100b = Reserved, 11=1011b = Reserved, 10=1010b = Reserved, 9=1001b = Reserved, 8=1000b = Reserved, 7=0111b = Reserved, 6=0110b = SOC is above its recommended upper limit, 5=0101b = SOC is at its recommended upper limit, 4=0100b = SOC is approaching its recommended upper limit, 3=0011b = SOC is below its recommended lower limit, 2=0010b = SOC is at its recommended lower limit, 1=0001b = SOC is approaching its recommended lower limit, 0=0000b = SOC level is acceptable.; unit bit}, range phys 0..15, unit=bit, to Vehicle_Control_Unit  # Status of the High Voltage Energy Storage System (or Pack 1 in systems with only one pack) State of Charge (SOC). Note: A given HVES controller may not support all of the states. This parameter provides HVES system level information. If there are mu
          signal HS_CellBalSts: start 28, 2 bit, little-endian, data-type-policy=OVERRIDE, init-value=0, base-type=HS_CellBalSts_Coding, compu {3=11b = Not Available, 2=10b = Error, 1=01b = Cells are unbalanced, 0=00b = Cells are balanced; unit bit}, range phys 0..3, unit=bit, to Vehicle_Control_Unit  # Indicates whether or not the cells in the High Voltage Energy Storage System (or Pack 1 in systems with only one pack) are balanced. This parameter provides HVES system level information. If there are multiple packs in the system, then both individual
          signal HS_CellBalnAcv: start 30, 2 bit, little-endian, data-type-policy=OVERRIDE, init-value=0, base-type=HS_CellBalnAcv_Coding, compu {3=11b = Not Available, 2=10b = Error, 1=01b = Cell balancing is active, 0=00b = Cell balancing is not active; unit bit}, range phys 0..3, unit=bit, to Vehicle_Control_Unit  # Indicates whether or not the cells in the High Voltage Energy Storage System (or Pack 1 in systems with only one pack) are currently being balanced. This parameter provides HVES system level information. If there are multiple packs in the system, then
          signal HS_IntChrgrSts: start 32, 2 bit, little-endian, data-type-policy=OVERRIDE, init-value=0, base-type=HS_IntChrgrSts_Coding, compu {3=11b = Not Available, 2=10b = Error, 1=01b = Charging on, 0=00b = Charging off; unit bit}, range phys 0..3, unit=bit, to Vehicle_Control_Unit  # Indicates that the charger in this HVES instance is on. External chargers may use the External Energy Source Connection Status (SPN 7898) and related SPs. This parameter provides HVES system level information. If there are multiple packs in the syste
          signal HS_Sts1Ctr: start 36, 4 bit, little-endian, data-type-policy=OVERRIDE, init-value=0, base-type=HS_Sts1Ctr_Coding, compu {identical; unit bit}, range phys 0..15, unit=bit, to Vehicle_Control_Unit  # The message counter is used to detect situations where the transmitting ECU malfunction repeats the same frame all the time. The receiver of the information may use the counter parameter to detect this situation. The transmitting device will increase the
          signal HS_HiUBusCnctnSts: start 40, 4 bit, little-endian, data-type-policy=OVERRIDE, init-value=0, base-type=HS_HiUBusCnctnSts_Coding, compu {15=1111b = Not Available, 14=1110b = Error, 13=1101b = Reserved, 12=1100b = Reserved, 11=1011b = Reserved, 10=1010b = Reserved, 9=1001b = Reserved, 8=1000b = Reserved, 7=0111b = Reserved, 6=0110b = Reserved, 5=0101b = Reserved, 4=0100b = Disconnected; Precharge Failed. Indicates that the pre-charge function status cannot be determined or did not complete (e.g. Relay failure, insufficient HVES voltage, etc.)., 3=0011b = Disconnection in Process., 2=0010b = Connection in Process.or in the process of being closed., 1=0001b = Connected. All contactors are closed and the precharge relay is open. Typically results from the SPN 8123 (HVESS High-Voltage Bus Connect Command) ., 0=0000b = Disconnected. One or more contactors are open. State may result from the SPN 8123 (HVESS High-Voltage Bus Connect Command) or due to a limit being exceeded.; unit bit}, range phys 0..15, unit=bit, to Vehicle_Control_Unit  # This parameter provides high level feedback on the High Voltage Energy Storage System (or Pack 1 in systems with only one pack) high voltage bus connection. For specific contactor information, see SPN 8091 (HVESS High-Voltage Bus (Positive) Contactor St
          signal HS_OperationalSts: start 44, 4 bit, little-endian, data-type-policy=OVERRIDE, init-value=0, base-type=HS_OperationalSts_Coding, compu {15=1111b = Not Available, 14=1110b = Error, 13=1101b = Reserved, 12=1100b = Reserved, 11=1011b = Reserved, 10=1010b = Reserved, 9=1001b = Reserved, 8=1000b = Reserved, 7=0111b = Reserved, 6=0110b = Disabled by internal decision of HVES controller (e.g. malfunction, protection), 5=0101b = Disabled by external command. The HVES is in a non-operational state due to a Power Down Command, or the result of Operation Consent being revoked., 4=0100b = Emergency Power-Down In Process. This state is a response to Power Down Command state 10b., 3=0011b = Normal Power-Down in Process. This state is a response to Power Down Command state 01b., 2=0010b = Operational., 1=0001b = Initialization Complete, awaiting Operation Consent., 0=0000b = Initialization in process. The HVES controller is powering up.; unit bit}, range phys 0..15, unit=bit, to Vehicle_Control_Unit  # Provides feedback on where the High Voltage Energy Storage System (or Pack 1 in systems with only one pack) is in its operating spectrum, and includes feedback in response to the Operation Consent [i.e. SPN 8412 (HVESS Operation Consent)] and Power Down
          signal HS_NrofHPsRdy: start 48, 8 bit, little-endian, data-type-policy=OVERRIDE, init-value=0, base-type=HS_NrofHPsRdy_Coding, compu {identical; unit count}, range phys 0..250, unit=count, to Vehicle_Control_Unit  # The number of High Voltage Energy Storage Packs that are currently ready to provide high voltage energy or are actively providing high voltage energy in the HVESS system. This parameter will increment after contactors are closed.
          signal HS_Sts1CRC: start 56, 8 bit, little-endian, data-type-policy=OVERRIDE, init-value=0, base-type=HS_Sts1CRC_Coding, compu {identical; unit count}, range phys 0..255, unit=count, to Vehicle_Control_Unit  # The CRC is defined as follows: • Length: 8 bits • Polynomial: x^8+x^5+x^3+x^2+x+1 • Initial Value: FFh • Input Data Reflection: Not reflected • Result Data Reflection: Not reflected • XOR value: FFh SAE makes no claim of the functional saf
      frame HVESSD7_PGN61600: id 0x1CF0A0F3, from VIC, to Vehicle_Control_Unit, frame-length=8, can-addressing-mode=EXTENDED  # High Voltage Energy Storage System Data 7
        pdu HVESSD7_PGN61600: length=8, transmission-mode-condition{data-filter=data-filter-type=ALWAYS, i-signal-in-i-pdu=HVESSD7_PGN61600_HS_DchaEC}, transmission-mode-true-timing=cyclic-timing=time-period=0.1
          signal HS_DchaEC: start 0, 24 bit, little-endian, data-type-policy=OVERRIDE, init-value=0, base-type=HS_DchaEC_Coding, compu {phys=raw*0.001; unit kWh}, range phys 0..16449.535, unit=kWh, to Vehicle_Control_Unit  # The amount of stored electrical energy in High Voltage Energy Storage System (or Pack 1 in systems with only one pack) that is available for use by the hybrid system, i.e. “how full is the tank”. See SPN 8079 (HVESS Discharge Capacity) for Ampere-hours
          signal HS_ChEC: start 24, 24 bit, little-endian, data-type-policy=OVERRIDE, init-value=0, base-type=HS_ChEC_Coding, compu {phys=raw*0.001; unit kWh}, range phys 0..16449.535, unit=kWh, to Vehicle_Control_Unit  # The amount of unused electrical energy storage available to be filled by charging High Voltage Energy Storage System (or Pack 1 in systems with only one pack), i.e. “how much empty space is remaining in the tank”. See SPN 8080 (HVESS Charge Capacity) fo
          signal HS_MaxChULim: start 48, 16 bit, little-endian, data-type-policy=OVERRIDE, init-value=0, base-type=HS_MaxChULim_Coding, compu {phys=raw*0.05; unit V}, range phys 0..3212.75, unit=V, to Vehicle_Control_Unit  # The maximum voltage level not to be exceeded while charging the High Voltage Energy Storage System (or Pack 1 in systems with only one pack). If this parameter is not supported, the maximum charge voltage should be limited to SPN 8117 (HVESS Recommended
      frame CCVS1_PGN65265: id 0x18FEF121, from Vehicle_Control_Unit, to VIC, frame-length=8, can-addressing-mode=EXTENDED  # Cruise Control/Vehicle Speed 1
        pdu CCVS1_PGN65265: length=8, transmission-mode-condition{data-filter=data-filter-type=ALWAYS, i-signal-in-i-pdu=CCVS1_PGN65265_Engine_Shutdwn_Ovride_Swtch}, transmission-mode-true-timing=cyclic-timing=time-period=0.1
          signal Engine_Shutdwn_Ovride_Swtch: start 62, 2 bit, little-endian, data-type-policy=OVERRIDE, init-value=0, base-type=Engine_Shutdwn_Ovride_Swtch_Coding, compu {identical; unit bit}, range phys 0..3, unit=bit, to VIC  # Switch signal which indicates the position of the engine shutdown override switch. 00b = Off 01b = On 10b = Error 11b = Not available
          signal Engine_Diag_Test_Mode_Swtch: start 60, 2 bit, little-endian, data-type-policy=OVERRIDE, init-value=0, base-type=Engine_Diag_Test_Mode_Swtch_Coding, compu {identical; unit bit}, range phys 0..3, unit=bit, to VIC  # Switch signal which indicates the position of the engine diagnostic test mode switch. 00b = Off 01b = On 10b = Error 11b = Not available
          signal Engine_Idle_Decrement_Switch: start 58, 2 bit, little-endian, data-type-policy=OVERRIDE, init-value=0, base-type=Engine_Idle_Decrement_Switch_Coding, compu {identical; unit bit}, range phys 0..3, unit=bit, to VIC  # Switch signal which indicates the position of the idle decrement switch. 00b = Off 01b = On 10b = Error 11b = Not available
          signal Engine_Idle_Increment_Switch: start 56, 2 bit, little-endian, data-type-policy=OVERRIDE, init-value=0, base-type=Engine_Idle_Increment_Switch_Coding, compu {identical; unit bit}, range phys 0..3, unit=bit, to VIC  # Switch signal which indicates the position of the idle increment switch. 00b = Off 01b = On 10b = Error 11b = Not available
          signal Cruise_Control_States: start 53, 3 bit, little-endian, data-type-policy=OVERRIDE, init-value=0, base-type=Cruise_Control_States_Coding, compu {identical; unit bit}, range phys 0..7, unit=bit, to VIC  # This parameter is used to indicate the current state, or mode, of operation by the cruise control device. 000b = Off/Disabled 001b = Hold 010b = Accelerate 011b = Decelerate 100b = Resume 101b = Set 110b = Accel Override 111b = Not available
          signal PTO_Governor_State: start 48, 5 bit, little-endian, data-type-policy=OVERRIDE, init-value=0, base-type=PTO_Governor_State_Coding, compu {identical; unit bit}, range phys 0..31, unit=bit, to VIC  # This parameter is used to indicate the current state or mode of operation by the power takeoff (PTO) governor. 00000b = Off/Disabled 00001b = Hold 00010b = Remote Hold 00011b = Standby 00100b = Remote Standby 00101b = Set
          signal Cruise_Control_Set_Spd: start 40, 8 bit, little-endian, data-type-policy=OVERRIDE, init-value=0, base-type=Cruise_Control_Set_Spd_Coding, compu {identical; unit km/h}, range phys 0..250, unit=km/h, to VIC  # Value of set (chosen) velocity of velocity control system. If an algorithm that can modify the cruise control set point exists in the system.
          signal Cruise_Control_Accelerate_Swtch: start 38, 2 bit, little-endian, data-type-policy=OVERRIDE, init-value=0, base-type=Cruise_Control_Accelerate_Swtch_Coding, compu {identical; unit bit}, range phys 0..3, unit=bit, to VIC  # Switch signal of the cruise control activator which indicates that the activator is in the position accelerate. 00b = Cruise control act not in the pos accel 01b = Cruise control activator in position accelerate 10b = Error 11b = Not available
          signal Cruise_Control_Resume_Swtch: start 36, 2 bit, little-endian, data-type-policy=OVERRIDE, init-value=0, base-type=Cruise_Control_Resume_Swtch_Coding, compu {identical; unit bit}, range phys 0..3, unit=bit, to VIC  # Switch signal of the cruise control activator which indicates that the activator is in the position resume. 00b = Cruise control act not in the pos resume 01b = Cruise control activator in position resume 10b = Error 11b = Not available
          signal Cruise_Control_Coast_Decl_Switch: start 34, 2 bit, little-endian, data-type-policy=OVERRIDE, init-value=0, base-type=Cruise_Control_Coast_Decl_Switch_Coding, compu {identical; unit bit}, range phys 0..3, unit=bit, to VIC  # Switch signal of the cruise control activator which indicates that the activator is in the position coast (decelerate). 00b = Cruise control act not in the pos coast 01b = Cruise control activator in position coast 10b = Error 11b = Not available
          signal Cruise_Control_SetSwtch: start 32, 2 bit, little-endian, data-type-policy=OVERRIDE, init-value=0, base-type=Cruise_Control_SetSwtch_Coding, compu {identical; unit bit}, range phys 0..3, unit=bit, to VIC  # Switch signal of the cruise control activator which indicates that the activator is in the position set. 00b = Cruise control activator not in the position set 01b = Cruise control activator in position set 10b = Error 11b = Not available
          signal Clutch_Switch: start 30, 2 bit, little-endian, data-type-policy=OVERRIDE, init-value=0, base-type=Clutch_Switch_Coding, compu {identical; unit bit}, range phys 0..3, unit=bit, to VIC  # Switch signal which indicates that the clutch pedal is being pressed. 00b = Clutch pedal released 01b = Clutch pedal depressed 10b = Error 11b = Not available
          signal Brake_Switch: start 28, 2 bit, little-endian, data-type-policy=OVERRIDE, init-value=0, base-type=Brake_Switch_Coding, compu {identical; unit bit}, range phys 0..3, unit=bit, to VIC  # Switch signal which indicates that the driver operated brake foot pedal is being pressed. 00b = Brake pedal released 01b = Brake pedal depressed 10b = Error 11b = Not Available
          signal Cruise_Control_Enable_Swtch: start 26, 2 bit, little-endian, data-type-policy=OVERRIDE, init-value=0, base-type=Cruise_Control_Enable_Swtch_Coding, compu {identical; unit bit}, range phys 0..3, unit=bit, to VIC  # Switch signal which indicates that it is possible to manage the cruise control function. 00b = Cruise control disabled 01b = Cruise control enabled 10b = Error 11b = Not available
          signal Cruise_Control_Active: start 24, 2 bit, little-endian, data-type-policy=OVERRIDE, init-value=0, base-type=Cruise_Control_Active_Coding, compu {identical; unit bit}, range phys 0..3, unit=bit, to VIC  # Cruise control is switched on. It is not ensured that the engine is controlled by cruise control. 00b = Cruise control switched off 01b = Cruise control switched on 10b = Error 11b = Not available
          signal Wheel_Based_Veh_Spd: start 8, 16 bit, little-endian, data-type-policy=OVERRIDE, init-value=0, base-type=Wheel_Based_Veh_Spd_Coding, compu {phys=raw/256; unit km/h}, range phys 0..250.996, unit=km/h, to VIC  # Speed of the vehicle as calculated from wheel or tailshaft speed.
          signal Cruise_Control_Pause_Swtch: start 4, 2 bit, little-endian, data-type-policy=OVERRIDE, init-value=0, base-type=Cruise_Control_Pause_Swtch_Coding, compu {identical; unit bit}, range phys 0..3, unit=bit, to VIC  # Switch signal which indicates the position of the Cruise Control Pause Switch used on Remote Cruise Control applications. 00b = Off 01b = On 10b = Error Indicator 11b = Take No Action
          signal Park_Brake_Rel_Inhibit_Req: start 6, 2 bit, little-endian, data-type-policy=OVERRIDE, init-value=0, base-type=Park_Brake_Rel_Inhibit_Req_Coding, compu {identical; unit bit}, range phys 0..3, unit=bit, to VIC  # Park Brake Release Inhibit Request signals the desire that an applied park brake remain applied and limit the ability of the vehicle to be moved. 00b = Park Brake Release Inhibit not req 01b = P B R InhtR 10b = SAE reserved 11b = Unavailable
          signal Parking_Brake_Swtch: start 2, 2 bit, little-endian, data-type-policy=OVERRIDE, init-value=0, base-type=Parking_Brake_Swtch_Coding, compu {identical; unit bit}, range phys 0..3, unit=bit, to VIC  # Switch signal which indicates when the parking brake is set. In general the switch actuated by the operator's park brake control. 00b = Parking brake not set 01b = Parking brake set 10b = Error 11b = Not available
          signal Two_Spd_Axle_Switch: start 0, 2 bit, little-endian, data-type-policy=OVERRIDE, init-value=0, base-type=Two_Spd_Axle_Switch_Coding, compu {identical; unit bit}, range phys 0..3, unit=bit, to VIC  # Switch signal which indicates the current axle range. 00b = Low speed range 01b = High speed range 10b = Error 11b = Not available
      frame HVESSHIST_PGN64606: id 0x1CFC5EF3, from VIC, to Vehicle_Control_Unit, frame-length=19, can-addressing-mode=EXTENDED  # High Voltage Energy Storage System History
        pdu HVESSHIST_PGN64606: length=19
          signal HS_StofHealth: start 0, 8 bit, little-endian, data-type-policy=OVERRIDE, init-value=0, base-type=HS_StofHealth_Coding, compu {phys=raw*0.4; unit %}, range phys 0..100, unit=%, to Vehicle_Control_Unit  # This signal represents the expected remaining 'Life' of the High Voltage Energy Storage System (or Pack 1 in systems with only one pack), in percent. Battery life is a manufacturer-specific measure of how well the energy storage system is functioning re
          signal HS_CtctrOpenUnderLoaCt: start 8, 16 bit, little-endian, data-type-policy=OVERRIDE, init-value=0, base-type=HS_CtctrOpenUnderLoaCt_Coding, compu {identical; unit count}, range phys 0..64255, unit=count, to Vehicle_Control_Unit  # This signal represents the number of times the contactors inside the High Voltage Energy Storage System (or Pack 1 in systems with only one pack) have opened while current is flowing through them. The current level (that determines if an opening event w
          signal HS_TotEThroughput: start 24, 32 bit, little-endian, data-type-policy=OVERRIDE, init-value=0, base-type=HS_TotEThroughput_Coding, compu {phys=raw*100; unit Watt-hour}, range phys 0..421108121500, unit=Watt-hour, to Vehicle_Control_Unit  # The total energy throughput which has flowed through High Voltage Energy Storage System (or Pack 1 in systems with only one pack). This parameter is the sum of the absolute values of the Energy into and out of this HVES instance. This parameter pro
          signal HS_TotAccumdCh: start 56, 32 bit, little-endian, data-type-policy=OVERRIDE, init-value=0, base-type=HS_TotAccumdCh_Coding, compu {phys=raw*100; unit Ah}, range phys 0..421108121500, unit=Ah, to Vehicle_Control_Unit  # The total accumulated amp hours which have flowed through High Voltage Energy Storage System (or Pack 1 in systems with only one pack). This parameter is the sum of the absolute values of the Ampere hours into and out of this HVES instance. This pa
          signal HS_TotLifetimeEInp: start 88, 32 bit, little-endian, data-type-policy=OVERRIDE, init-value=0, base-type=HS_TotLifetimeEInp_Coding, compu {identical; unit kWh}, range phys 0..4211081215, unit=kWh, to Vehicle_Control_Unit  # The cumulative energy which has flowed into the High Voltage Energy Storage System over the lifetime of the battery system (or Pack 1 in systems with only one pack). In multipack systems this parameter is the sum of the individual packs (See SPN 13367 (
          signal HS_TotLifetimeEOutp: start 120, 32 bit, little-endian, data-type-policy=OVERRIDE, init-value=0, base-type=HS_TotLifetimeEOutp_Coding, compu {identical; unit kWh}, range phys 0..4211081215, unit=kWh, to Vehicle_Control_Unit  # The cumulative energy which has flowed out of the High Voltage Energy Storage System over the lifetime of the battery system (or Pack 1 in systems with only one pack). In multipack systems this parameter is the sum of the individual packs (See SPN 13368
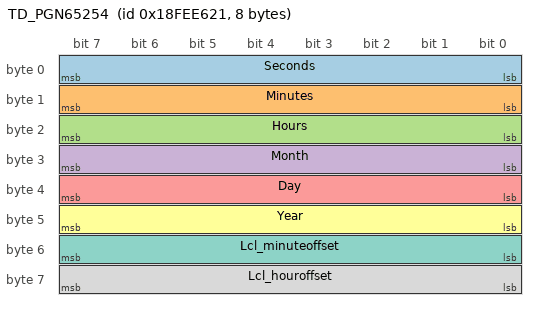
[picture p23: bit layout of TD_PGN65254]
      frame TD_PGN65254: id 0x18FEE621, from Vehicle_Control_Unit, to VIC, frame-length=8, can-addressing-mode=EXTENDED  # Time/Date
        pdu TD_PGN65254: length=8
          signal Seconds: start 0, 8 bit, little-endian, data-type-policy=OVERRIDE, init-value=0, base-type=Seconds_Coding, compu {phys=raw*0.25; unit s}, range phys 0..62.5, unit=s, to VIC  # The seconds component of the current time of day. This should be reported as the seconds component of the current time at UTC (Universal Time Coordinate), a.k.a. GMT; however, it may be reported as the seconds component of the current time at a local ti
          signal Minutes: start 8, 8 bit, little-endian, data-type-policy=OVERRIDE, init-value=0, base-type=Minutes_Coding, compu {identical; unit min}, range phys 0..250, unit=min, to VIC  # The minutes component of the current time of day. This should be reported as the minutes component of the current time at UTC (Universal Time Coordinate), a.k.a. GMT; however, it may be reported as the minutes component of the current time at a local ti
          signal Hours: start 16, 8 bit, little-endian, data-type-policy=OVERRIDE, init-value=0, base-type=Hours_Coding, compu {identical; unit h}, range phys 0..250, unit=h, to VIC  # The hour component of the current time of day. This should be reported as the hour component of the current time at UTC (Universal Time Coordinate), a.k.a. GMT; however, it may be reported as the hour component of the current time at a local time zone.
          signal Month: start 24, 8 bit, little-endian, data-type-policy=OVERRIDE, init-value=0, base-type=Month_Coding, compu {identical; unit months}, range phys 0..250, unit=months, to VIC  # The month component of the current calendar date. This should be reported as the month component of the current date at UTC (Universal Time Coordinate), a.k.a. GMT; however, it may be reported as the month component of the current date at a local time z
          signal Day: start 32, 8 bit, little-endian, data-type-policy=OVERRIDE, init-value=0, base-type=Day_Coding, compu {phys=raw*0.25; unit days}, range phys 0..62.5, unit=days, to VIC  # The day component of the current calendar date. This should be reported as the day component of the current date at UTC (Universal Time Coordinate), a.k.a. GMT; however, it may be reported as the day component of the current date at a local time zone.
          signal Year: start 40, 8 bit, little-endian, data-type-policy=OVERRIDE, init-value=0, base-type=Year_Coding, compu {phys=raw+1985; unit years}, range phys 1985..2235, unit=years, to VIC  # The year component of the current calendar date. This should be reported as the year component of the current date at UTC (Universal Time Coordinate), a.k.a. GMT; however, it may be reported as the year component of the current date at a local time zone
          signal Lcl_minuteoffset: start 48, 8 bit, little-endian, data-type-policy=OVERRIDE, init-value=0, base-type=Lcl_minuteoffset_Coding, compu {phys=raw-125; unit min}, range phys -125..125, unit=min, to VIC  # The minute component of the offset between the UTC time and date and a local time zone time and date. This is the number of minutes to add to UTC (Universal Time Coordinate) time and date to convert to the time and date in the local time zone . The Loc
          signal Lcl_houroffset: start 56, 8 bit, little-endian, data-type-policy=OVERRIDE, init-value=0, base-type=Lcl_houroffset_Coding, compu {phys=raw-125; unit h}, range phys -125..125, unit=h, to VIC  # The hour component of the offset between the UTC (Universal Time Coordinate) time and date and a local time zone time and date. This is the number of hours to add to UTC, a.k.a. GMT, time and date to convert to the time and date in the local time zone.
      frame AMB_PGN65269: id 0x18FEF521, from Vehicle_Control_Unit, to VIC, frame-length=8, can-addressing-mode=EXTENDED  # Ambient Conditions
        pdu AMB_PGN65269: length=8, transmission-mode-condition{data-filter=data-filter-type=ALWAYS, i-signal-in-i-pdu=AMB_PGN65269_Barometric_P}, transmission-mode-true-timing=cyclic-timing=time-period=1
          signal Barometric_P: start 0, 8 bit, little-endian, data-type-policy=OVERRIDE, init-value=0, base-type=Barometric_P_Coding, compu {phys=raw*0.5; unit kPa}, range phys 0..125, unit=kPa, to VIC  # Absolute air pressure of the atmosphere.
          signal Cab_InteriorT: start 8, 16 bit, little-endian, data-type-policy=OVERRIDE, init-value=0, base-type=Cab_InteriorT_Coding, compu {phys=raw/32-273; unit °C}, range phys -273..1734.96875, unit=°C, to VIC  # Temperature of air inside the part of the vehicle that encloses the driver and vehicle operating controls. Note: See also SPN 1691. SPN 1662 is an additional diagnostic SP associated with cab temperature.
          signal Amb_AirT: start 24, 16 bit, little-endian, data-type-policy=OVERRIDE, init-value=0, base-type=Amb_AirT_Coding, compu {phys=raw/32-273; unit °C}, range phys -273..1734.96875, unit=°C, to VIC  # Temperature of air surrounding vehicle.
          signal Eng_Intk1AirT: start 40, 8 bit, little-endian, data-type-policy=OVERRIDE, init-value=0, base-type=Eng_Intk1AirT_Coding, compu {phys=raw-40; unit °C}, range phys -40..210, unit=°C, to VIC  # Temperature of air entering vehicle air induction system.
          signal Road_SurfT: start 48, 16 bit, little-endian, data-type-policy=OVERRIDE, init-value=0, base-type=Road_SurfT_Coding, compu {phys=raw/32-273; unit °C}, range phys -273..1734.96875, unit=°C, to VIC  # Indicated temperature of road surface over which vehicle is operating.
